AUTOSAR XML (schema 00050)
package /RB/PT/PCT_MDG1_FlatView/SwComponentTypes
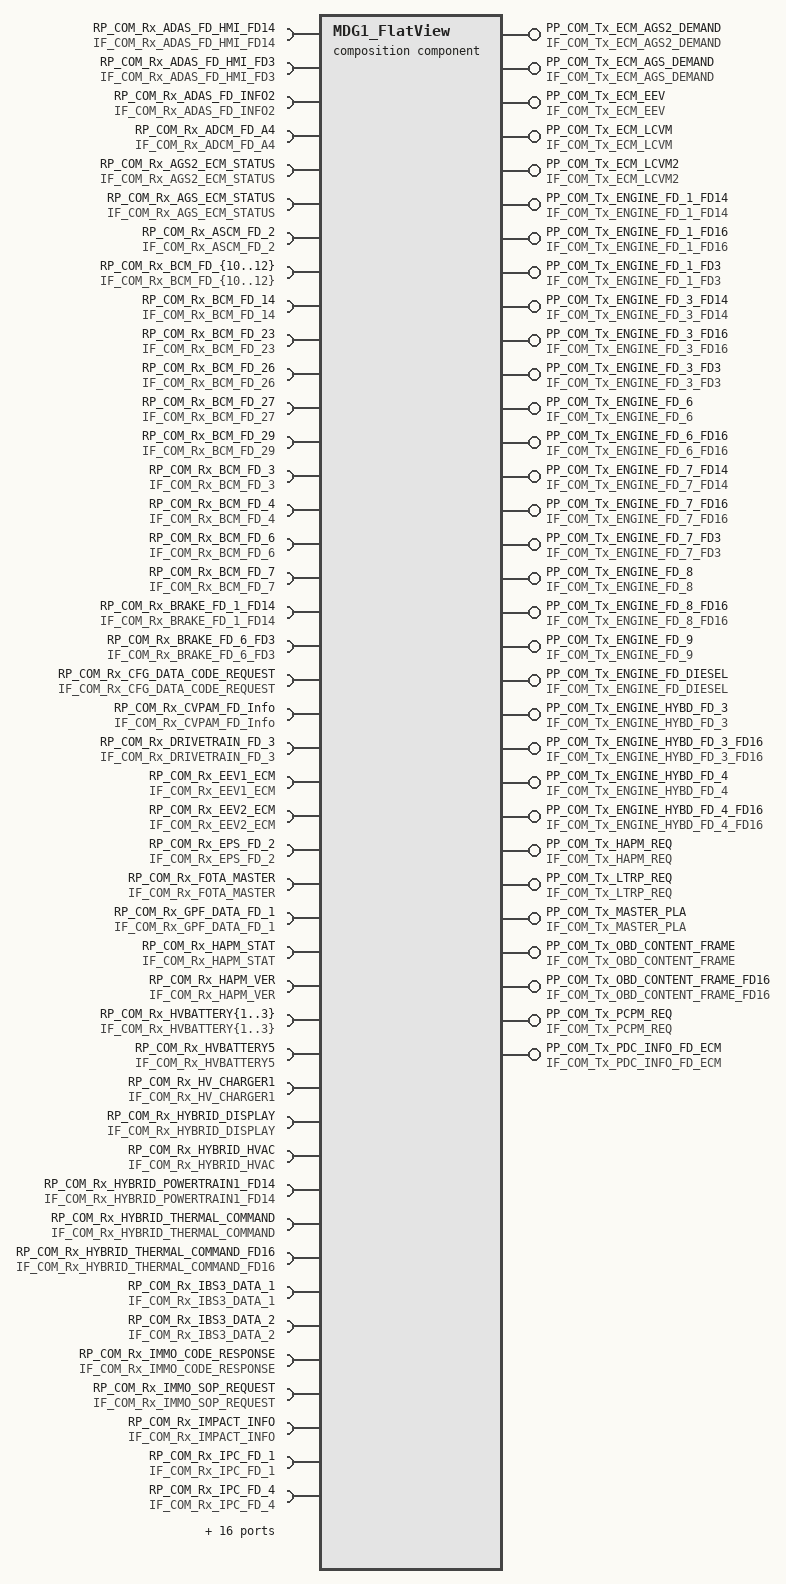
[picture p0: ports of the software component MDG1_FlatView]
  composition sw component type MDG1_FlatView
    31 x provide port:
      PP_COM_Tx_ECM_AGS2_DEMAND: provided-interface=IF_COM_Tx_ECM_AGS2_DEMAND
      PP_COM_Tx_ECM_AGS_DEMAND: provided-interface=IF_COM_Tx_ECM_AGS_DEMAND
      PP_COM_Tx_ECM_EEV: provided-interface=IF_COM_Tx_ECM_EEV
      PP_COM_Tx_ECM_LCVM: provided-interface=IF_COM_Tx_ECM_LCVM
      PP_COM_Tx_ECM_LCVM2: provided-interface=IF_COM_Tx_ECM_LCVM2
      PP_COM_Tx_ENGINE_FD_1_FD14: provided-interface=IF_COM_Tx_ENGINE_FD_1_FD14
      PP_COM_Tx_ENGINE_FD_1_FD16: provided-interface=IF_COM_Tx_ENGINE_FD_1_FD16
      PP_COM_Tx_ENGINE_FD_1_FD3: provided-interface=IF_COM_Tx_ENGINE_FD_1_FD3
      PP_COM_Tx_ENGINE_FD_3_FD14: provided-interface=IF_COM_Tx_ENGINE_FD_3_FD14
      PP_COM_Tx_ENGINE_FD_3_FD16: provided-interface=IF_COM_Tx_ENGINE_FD_3_FD16
      PP_COM_Tx_ENGINE_FD_3_FD3: provided-interface=IF_COM_Tx_ENGINE_FD_3_FD3
      PP_COM_Tx_ENGINE_FD_6: provided-interface=IF_COM_Tx_ENGINE_FD_6
      PP_COM_Tx_ENGINE_FD_6_FD16: provided-interface=IF_COM_Tx_ENGINE_FD_6_FD16
      PP_COM_Tx_ENGINE_FD_7_FD14: provided-interface=IF_COM_Tx_ENGINE_FD_7_FD14
      PP_COM_Tx_ENGINE_FD_7_FD16: provided-interface=IF_COM_Tx_ENGINE_FD_7_FD16
      PP_COM_Tx_ENGINE_FD_7_FD3: provided-interface=IF_COM_Tx_ENGINE_FD_7_FD3
      PP_COM_Tx_ENGINE_FD_8: provided-interface=IF_COM_Tx_ENGINE_FD_8
      PP_COM_Tx_ENGINE_FD_8_FD16: provided-interface=IF_COM_Tx_ENGINE_FD_8_FD16
      PP_COM_Tx_ENGINE_FD_9: provided-interface=IF_COM_Tx_ENGINE_FD_9
      PP_COM_Tx_ENGINE_FD_DIESEL: provided-interface=IF_COM_Tx_ENGINE_FD_DIESEL
      PP_COM_Tx_ENGINE_HYBD_FD_3: provided-interface=IF_COM_Tx_ENGINE_HYBD_FD_3
      PP_COM_Tx_ENGINE_HYBD_FD_3_FD16: provided-interface=IF_COM_Tx_ENGINE_HYBD_FD_3_FD16
      PP_COM_Tx_ENGINE_HYBD_FD_4: provided-interface=IF_COM_Tx_ENGINE_HYBD_FD_4
      PP_COM_Tx_ENGINE_HYBD_FD_4_FD16: provided-interface=IF_COM_Tx_ENGINE_HYBD_FD_4_FD16
      PP_COM_Tx_HAPM_REQ: provided-interface=IF_COM_Tx_HAPM_REQ
      PP_COM_Tx_LTRP_REQ: provided-interface=IF_COM_Tx_LTRP_REQ
      PP_COM_Tx_MASTER_PLA: provided-interface=IF_COM_Tx_MASTER_PLA
      PP_COM_Tx_OBD_CONTENT_FRAME: provided-interface=IF_COM_Tx_OBD_CONTENT_FRAME
      PP_COM_Tx_OBD_CONTENT_FRAME_FD16: provided-interface=IF_COM_Tx_OBD_CONTENT_FRAME_FD16
      PP_COM_Tx_PCPM_REQ: provided-interface=IF_COM_Tx_PCPM_REQ
      PP_COM_Tx_PDC_INFO_FD_ECM: provided-interface=IF_COM_Tx_PDC_INFO_FD_ECM
    64 x require port:
      RP_COM_Rx_ADAS_FD_HMI_FD14: required-interface=IF_COM_Rx_ADAS_FD_HMI_FD14
      RP_COM_Rx_ADAS_FD_HMI_FD3: required-interface=IF_COM_Rx_ADAS_FD_HMI_FD3
      RP_COM_Rx_ADAS_FD_INFO2: required-interface=IF_COM_Rx_ADAS_FD_INFO2
      RP_COM_Rx_ADCM_FD_A4: required-interface=IF_COM_Rx_ADCM_FD_A4
      RP_COM_Rx_AGS2_ECM_STATUS: required-interface=IF_COM_Rx_AGS2_ECM_STATUS
      RP_COM_Rx_AGS_ECM_STATUS: required-interface=IF_COM_Rx_AGS_ECM_STATUS
      RP_COM_Rx_ASCM_FD_2: required-interface=IF_COM_Rx_ASCM_FD_2
      RP_COM_Rx_BCM_FD_{10..12}: required-interface=IF_COM_Rx_BCM_FD_{10..12}
      RP_COM_Rx_BCM_FD_14: required-interface=IF_COM_Rx_BCM_FD_14
      RP_COM_Rx_BCM_FD_23: required-interface=IF_COM_Rx_BCM_FD_23
      RP_COM_Rx_BCM_FD_26: required-interface=IF_COM_Rx_BCM_FD_26
      RP_COM_Rx_BCM_FD_27: required-interface=IF_COM_Rx_BCM_FD_27
      RP_COM_Rx_BCM_FD_29: required-interface=IF_COM_Rx_BCM_FD_29
      RP_COM_Rx_BCM_FD_3: required-interface=IF_COM_Rx_BCM_FD_3
      RP_COM_Rx_BCM_FD_4: required-interface=IF_COM_Rx_BCM_FD_4
      RP_COM_Rx_BCM_FD_6: required-interface=IF_COM_Rx_BCM_FD_6
      RP_COM_Rx_BCM_FD_7: required-interface=IF_COM_Rx_BCM_FD_7
      RP_COM_Rx_BRAKE_FD_1_FD14: required-interface=IF_COM_Rx_BRAKE_FD_1_FD14
      RP_COM_Rx_BRAKE_FD_6_FD3: required-interface=IF_COM_Rx_BRAKE_FD_6_FD3
      RP_COM_Rx_CFG_DATA_CODE_REQUEST: required-interface=IF_COM_Rx_CFG_DATA_CODE_REQUEST
      RP_COM_Rx_CVPAM_FD_Info: required-interface=IF_COM_Rx_CVPAM_FD_Info
      RP_COM_Rx_DRIVETRAIN_FD_3: required-interface=IF_COM_Rx_DRIVETRAIN_FD_3
      RP_COM_Rx_EEV1_ECM: required-interface=IF_COM_Rx_EEV1_ECM
      RP_COM_Rx_EEV2_ECM: required-interface=IF_COM_Rx_EEV2_ECM
      RP_COM_Rx_EPS_FD_2: required-interface=IF_COM_Rx_EPS_FD_2
      RP_COM_Rx_FOTA_MASTER: required-interface=IF_COM_Rx_FOTA_MASTER
      RP_COM_Rx_GPF_DATA_FD_1: required-interface=IF_COM_Rx_GPF_DATA_FD_1
      RP_COM_Rx_HAPM_STAT: required-interface=IF_COM_Rx_HAPM_STAT
      RP_COM_Rx_HAPM_VER: required-interface=IF_COM_Rx_HAPM_VER
      RP_COM_Rx_HVBATTERY{1..3}: required-interface=IF_COM_Rx_HVBATTERY{1..3}
      RP_COM_Rx_HVBATTERY5: required-interface=IF_COM_Rx_HVBATTERY5
      RP_COM_Rx_HV_CHARGER1: required-interface=IF_COM_Rx_HV_CHARGER1
      RP_COM_Rx_HYBRID_DISPLAY: required-interface=IF_COM_Rx_HYBRID_DISPLAY
      RP_COM_Rx_HYBRID_HVAC: required-interface=IF_COM_Rx_HYBRID_HVAC
      RP_COM_Rx_HYBRID_POWERTRAIN1_FD14: required-interface=IF_COM_Rx_HYBRID_POWERTRAIN1_FD14
      RP_COM_Rx_HYBRID_THERMAL_COMMAND: required-interface=IF_COM_Rx_HYBRID_THERMAL_COMMAND
      RP_COM_Rx_HYBRID_THERMAL_COMMAND_FD16: required-interface=IF_COM_Rx_HYBRID_THERMAL_COMMAND_FD16
      RP_COM_Rx_IBS3_DATA_1: required-interface=IF_COM_Rx_IBS3_DATA_1
      RP_COM_Rx_IBS3_DATA_2: required-interface=IF_COM_Rx_IBS3_DATA_2
      RP_COM_Rx_IMMO_CODE_RESPONSE: required-interface=IF_COM_Rx_IMMO_CODE_RESPONSE
      RP_COM_Rx_IMMO_SOP_REQUEST: required-interface=IF_COM_Rx_IMMO_SOP_REQUEST
      RP_COM_Rx_IMPACT_INFO: required-interface=IF_COM_Rx_IMPACT_INFO
      RP_COM_Rx_IPC_FD_1: required-interface=IF_COM_Rx_IPC_FD_1
      RP_COM_Rx_IPC_FD_4: required-interface=IF_COM_Rx_IPC_FD_4
      RP_COM_Rx_IPC_VEHICLE_SETUP: required-interface=IF_COM_Rx_IPC_VEHICLE_SETUP
      RP_COM_Rx_LCVM2_ECM: required-interface=IF_COM_Rx_LCVM2_ECM
      RP_COM_Rx_LCVM_ECM: required-interface=IF_COM_Rx_LCVM_ECM
      RP_COM_Rx_LTRP_STAT: required-interface=IF_COM_Rx_LTRP_STAT
      RP_COM_Rx_LTRP_VER: required-interface=IF_COM_Rx_LTRP_VER
      RP_COM_Rx_PCPM_Stat: required-interface=IF_COM_Rx_PCPM_Stat
      RP_COM_Rx_PCPM_VER: required-interface=IF_COM_Rx_PCPM_VER
      RP_COM_Rx_PLA_INFO: required-interface=IF_COM_Rx_PLA_INFO
      RP_COM_Rx_PT_SYSTEM_FD_1_FD3: required-interface=IF_COM_Rx_PT_SYSTEM_FD_1_FD3
      RP_COM_Rx_RFHUB_FD_1: required-interface=IF_COM_Rx_RFHUB_FD_1
      RP_COM_Rx_STEERING1: required-interface=IF_COM_Rx_STEERING1
      RP_COM_Rx_TELEMATIC_FD_1: required-interface=IF_COM_Rx_TELEMATIC_FD_1
      RP_COM_Rx_TELEMATIC_FD_11: required-interface=IF_COM_Rx_TELEMATIC_FD_11
      RP_COM_Rx_TELEMATIC_FD_14: required-interface=IF_COM_Rx_TELEMATIC_FD_14
      RP_COM_Rx_TELEMATIC_FD_5: required-interface=IF_COM_Rx_TELEMATIC_FD_5
      RP_COM_Rx_VSIM_FD_1: required-interface=IF_COM_Rx_VSIM_FD_1
    191 x component:
      AC_CluRlyDigOutp: type=IoSigDioOutp_SwSStellantis
      AirCdngPSnsrAdcInpSwc: type=IoSigAdc_SwSStellantis
      AllGrPosnSnsr1PwmInp: type=IoSigPwmInp_SwSStellantis
      AllGrPosnSnsr2PwmInp: type=IoSigPwmInp_SwSStellantis
      AlterFieCtrlPwmOutp: type=IoSigPwmOutp_SwSStellantis
      BoostTemp1AdcInpSwc: type=IoSigAdc_SwSStellantis
      BoostTemp2AdcInpSwc: type=IoSigAdc_SwSStellantis
      BrkPdlPosnSnsrAdcInp: type=IoSigAdc_SwSStellantis
      BrkSwDigInp: type=IoSigDioInp_SwSStellantis
      CEGR_PosnSns: type=SentStack_SwSStellantis
      CPT_BswM: type=BswM
      CPT_ComCIL_Adapt: type=SWC_ComCIL_Adapt
      CPT_ComDia_Dcm_Rte_Adapter: type=ComDia_Dcm_Rte_Adapter
      CPT_ComM: type=ComM
      CPT_ComScl_EngLin: type=SWC_ComScl_EngLin
      CPT_ComScl_EngLin_Scl: type=SWC_ComScl_EngLin_Scl
      CPT_ComScl_NetMtrx: type=SWC_ComScl_NetMtrx
      CPT_ComScl_NetMtrx2: type=SWC_ComScl_NetMtrx2
      CPT_ComScl_NetMtrx2_Scl: type=SWC_ComScl_NetMtrx2_Scl
      CPT_ComScl_NetMtrx3: type=SWC_ComScl_NetMtrx3
      CPT_ComScl_NetMtrx3_Scl: type=SWC_ComScl_NetMtrx3_Scl
      CPT_ComScl_NetMtrx_Scl: type=SWC_ComScl_NetMtrx_Scl
      CPT_Csm: type=Csm
      CPT_Dcm: type=Dcm
      CPT_Dem: type=Dem
      CPT_Det: type=Det
      CPT_ESC_EveCfg: type=ESC_EveCfg
      CPT_ESC_HwIntrptEveGen: type=ESC_HwIntrptEveGen
      CPT_ESC_Ladp: type=ESC_Ladp
      CPT_ESC_OsTskActvnHndlr: type=ESC_OsTskActvnHndlr
      CPT_EcuM: type=EcuM
      CPT_Epm_Ladp: type=Epm_Ladp
      CPT_FiM: type=FiM
      CPT_IoSigAdc_SwSStellantisParm: type=IoSigAdc_SwSStellantisParm
      CPT_IoSigDioInp_SwSStellantisParam: type=IoSigDioInp_SwSStellantisParam
      CPT_IoSigDioOutp_SwSStellantisParam: type=IoSigDioOutp_SwSStellantisParam
      CPT_IoSigPwmInp_SwSStellantisParm: type=IoSigPwmInp_SwSStellantisParm
      CPT_IoSigPwmOutp_SwSStellantisParm: type=IoSigPwmOutp_SwSStellantisParm
      CPT_KeyM: type=KeyM
      CPT_NvM: type=NvM
      CPT_SWC_VcodProxi: type=SWC_VcodProxi
      CPT_SecOC: type=SecOC
      CPT_SentStack_SwSStellantisParm: type=SentStack_SwSStellantisParm
      CPT_SysC_Ladp: type=SysC_Ladp
      CPT_WdgM: type=WdgM
      CPT_esc_stack: type=esc_stack
      CPT_esc_tasklink: type=esc_tasklink
      CPT_rba_DiagLib: type=rba_DiagLib
      CPT_rba_IoDiagHbr: type=rba_IoDiagHbr
      CPT_rba_IoDiagHlfBr: type=rba_IoDiagHlfBr
      CPT_rba_IoDiagPs: type=rba_IoDiagPs
      CPT_rba_IoDiagPwr: type=rba_IoDiagPwr
      CPT_rba_IoSigAdc: type=rba_IoSigAdc
      CPT_rba_IoSigDio: type=rba_IoSigDio
      CPT_rba_IoSigHlfBr: type=rba_IoSigHlfBr
      CPT_rba_IoSigIcu: type=rba_IoSigIcu
      CPT_rba_IoSigObs: type=rba_IoSigObs
      CPT_rba_IoSigPwm: type=rba_IoSigPwm
      CPT_rba_IoSigPwr: type=rba_IoSigPwr
      CPT_rba_IoSigRtc: type=rba_IoSigRtc
      CPT_rba_OsArSchedExtn_OS: type=rba_OsArSchedExtn_OS
      CPT_rba_OsShell: type=rba_OsShell
      CPT_rba_SyC_States: type=rba_SyC_States
      CPT_rba_SyC_States_Cfg_0_Q_1: type=rba_SyC_States_Cfg_0_Q_1
      CPT_rba_SyC_States_Cfg_1_B_1: type=rba_SyC_States_Cfg_1_B_1
      CPT_rba_SyC_States_Cfg_{1..3}_Q_1: type=rba_SyC_States_Cfg_{1..3}_Q_1
      CPT_rbf_SftyHw_ErrMngtModl: type=rbf_SftyHw_ErrMngtModl
      CPT_rbf_SftyHw_ProgFlowChk: type=rbf_SftyHw_ProgFlowChk
      CPT_rbf_SftyHw_ShtOffPahPwrStg: type=rbf_SftyHw_ShtOffPahPwrStg
      CPT_rbm_DSM_Conf: type=rbm_DSM_Conf
      CPT_rbm_MilHndlr: type=rbm_MilHndlr
      CalInp1AdcInpSwc: type=IoSigAdc_SwSStellantis
      CalInp2AdcInpSwc: type=IoSigAdc_SwSStellantis
      CluInterLockSwDigInp: type=IoSigDioInp_SwSStellantis
      CluSnsAdcInp: type=IoSigAdc_SwSStellantis
      CmprInletTempAdcInp: type=IoSigAdc_SwSStellantis
      CoEng_SwSStellantis: type=CoEng_SwSStellantis
      ColdCrkCasePSnsrAdcInpSwc: type=IoSigAdc_SwSStellantis
      CoolEgrTAdcInpSwc: type=IoSigAdc_SwSStellantis
      Coolt3WayVlvAdcInpSwc: type=IoSigAdc_SwSStellantis
      CooltInletTempAdcInpSwc: type=IoSigAdc_SwSStellantis
      CrkBattMonrAdcInpSwc: type=IoSigAdc_SwSStellantis
      DMTLLkPmpDigOutp: type=IoSigDioOutp_SwSStellantis
      DP_VlvPosnSns: type=SentStack_SwSStellantis
      DSM_SwSStellantis: type=DSM_SwSStellantis
      DualFuTankEnblRlyDigOutp: type=IoSigDioOutp_SwSStellantis
      DynoFuDsblReqSwDigInp: type=IoSigDioInp_SwSStellantis
      ECM_WakeUpDigInp: type=IoSigDioInp_SwSStellantis
      EGRCoolr_DeltAbsPresSnsr: type=SentStack_SwSStellantis
      ELCM_ChgOvrVlvDigOutp: type=IoSigDioOutp_SwSStellantis
      ELCM_VacPmpPwmOutp: type=IoSigPwmOutp_SwSStellantis
      ElecPhsrDiagPwmInp: type=IoSigPwmInp_SwSStellantis
      ElecPhsrMtrCmdOutpPwmOutp: type=IoSigPwmOutp_SwSStellantis
      ElectcVacPmpRlyDigOutp: type=IoSigDioOutp_SwSStellantis
      EngCooltTAdcInpSwc: type=IoSigAdc_SwSStellantis
      EngSwtBattAdcInpSwc: type=IoSigAdc_SwSStellantis
      EnvP_SwSStellantis: type=EnvP_SwSStellantis
      Epm_SwSStellantis: type=Epm_SwSStellantis
      Epm_SwSStellantis_PSwc: type=Epm_SwSStellantis_PSwc
      EvapLkChkMonSnsAdcInpSwc: type=IoSigAdc_SwSStellantis
      FPCMFb1PwmInp: type=IoSigPwmInp_SwSStellantis
      FiveVoltAuxAdcInpSwc: type=IoSigAdc_SwSStellantis
      FiveVoltOutpAdcInpSwc: type=IoSigAdc_SwSStellantis
      FiveVoltSnsAdcInpSwc: type=IoSigAdc_SwSStellantis
      FuDoorDigOutp: type=IoSigDioOutp_SwSStellantis
      FuDoorSwDigInp: type=IoSigDioInp_SwSStellantis
      FuPmpCtlMdul2CmdPwmOutp: type=IoSigPwmOutp_SwSStellantis
      FuPmpCtlMdulCmdPwmOutp: type=IoSigPwmOutp_SwSStellantis
      FuTankIsolnVlvDigOutp: type=IoSigDioOutp_SwSStellantis
      FuTankPSnsrAdcInpSwc: type=IoSigAdc_SwSStellantis
      GEVlv_SwSStellantis: type=GEVlv_SwSStellantis
      GPF_DeltAbsPresSnsr1: type=SentStack_SwSStellantis
      GPF_DeltAbsPresSnsr2: type=SentStack_SwSStellantis
      GdiFuRailP1AdcInpSwc: type=IoSigAdc_SwSStellantis
      GdiFuRailP2AdcInpSwc: type=IoSigAdc_SwSStellantis
      HTR_MeclWtrPmpActrPwmOutp: type=IoSigPwmOutp_SwSStellantis
      HTR_TempCtrlVlvSolnPwmOutp: type=IoSigPwmOutp_SwSStellantis
      Hbrdg_Coold_EGR: type=IoSigHbrdg_SwSStellantis
      Hbrdg_DP: type=IoSigHbrdg_SwSStellantis
      Hbrdg_ETC_Motor: type=IoSigHbrdg_SwSStellantis
      Hbrdg_VarGeomTrb: type=IoSigHbrdg_SwSStellantis
      Hbrdg_Wg1: type=IoSigHbrdg_SwSStellantis
      HiTRadrOutlTSnsrAdcInpSwc: type=IoSigAdc_SwSStellantis
      HoodAjarAdcInpSwc: type=IoSigAdc_SwSStellantis
      IgnCl_SwSStellantis: type=IgnCl_SwSStellantis
      IgnRunStrtSwDigInp: type=IoSigDioInp_SwSStellantis
      InjSyG_SwSStellantis: type=InjSyG_SwSStellantis
      InjVvGPfi_SwSStellantis: type=InjVvGPfi_SwSStellantis
      InjVvG_SwSStellantis: type=InjVvG_SwSStellantis
      InrushCircRlyDigOutp: type=IoSigDioOutp_SwSStellantis
      IntkAirTAdcInpSwc: type=IoSigAdc_SwSStellantis
      IoSigAdc_SwSStellantisParm: type=IoSigAdc_SwSStellantisParm
      IoSigDioInp_SwSStellantisParam: type=IoSigDioInp_SwSStellantisParam
      IoSigDioOutp_SwSStellantisParam: type=IoSigDioOutp_SwSStellantisParam
      IoSigHbrdg_SwSStellantisParam: type=IoSigHbrdg_SwSStellantisParam
      IoSigIfAdapt_SwSStellantis: type=IoSigIfAdapt_SwSStellantis
      IoSigPwmInp_SwSStellantisParm: type=IoSigPwmInp_SwSStellantisParm
      IoSigPwmOutp_SwSStellantisParm: type=IoSigPwmOutp_SwSStellantisParm
      IoSigPwr_SwSStellantis: type=IoSigPwr_SwSStellantis
      KnDet_SwSStellantis: type=KnDet_SwSStellantis
      LoPFuSnsrAdcInpSwc: type=IoSigAdc_SwSStellantis
      LoPresFuPmpRlyDigOutp: type=IoSigDioOutp_SwSStellantis
      MAF_Hum_Snsr: type=SentStack_SwSStellantis
      MFVlv_SwSStellantis: type=MFVlv_SwSStellantis
      MaiRlyDigOutp: type=IoSigDioOutp_SwSStellantis
      MakeUpAirVlvDigOutp: type=IoSigDioOutp_SwSStellantis
      MnfldAirPAdcInpSwc: type=IoSigAdc_SwSStellantis
      MnfldGasTAdcInpSwc: type=IoSigAdc_SwSStellantis
      NVLD_SwDigInp: type=IoSigDioInp_SwSStellantis
      O2Snsr_SwSStellantis: type=O2Snsr_SwSStellantis
      OBD_PurgVentVlvDigOutp: type=IoSigDioOutp_SwSStellantis
      OilLvlSnsrPwmInp: type=IoSigPwmInp_SwSStellantis
      OilPSnsrAdcInpSwc: type=IoSigAdc_SwSStellantis
      OilShutOffValveFbAdcInp: type=IoSigAdc_SwSStellantis
      OilShutOffVlvDigOutp: type=IoSigDioOutp_SwSStellantis
      OilTSnsrAdcInpSwc: type=IoSigAdc_SwSStellantis
      PFIFuRailPressAdcInp: type=IoSigAdc_SwSStellantis
      PFIFuRailTempAdcInp: type=IoSigAdc_SwSStellantis
      PedlValSnsr1AdcInpSwc: type=IoSigAdc_SwSStellantis
      PedlValSnsr2AdcInpSwc: type=IoSigAdc_SwSStellantis
      PedlValSnsr2AuxAdcInpSwc: type=IoSigAdc_SwSStellantis
      PurgSoln2PwmOutp: type=IoSigPwmOutp_SwSStellantis
      PurgSolnPwmOutp: type=IoSigPwmOutp_SwSStellantis
      RadrFanCtrlPwmPwmOutp: type=IoSigPwmOutp_SwSStellantis
      RadrFanRlyHiSpdDigOutp: type=IoSigDioOutp_SwSStellantis
      ReAxleTempSnsrAdcInp: type=IoSigAdc_SwSStellantis
      SecdAirPmpRlyDigOutp: type=IoSigDioOutp_SwSStellantis
      SecdAirShutOffSoln1DigOutp: type=IoSigDioOutp_SwSStellantis
      SentStack_SwSStellantisParm: type=SentStack_SwSStellantisParm
      SrgSoln1DigOutp: type=IoSigDioOutp_SwSStellantis
      SrgSoln2DigOutp: type=IoSigDioOutp_SwSStellantis
      StrtrRlyDigOutp: type=IoSigDioOutp_SwSStellantis
      StrtrRlyFbDigInp: type=IoSigDioInp_SwSStellantis
      SwilEngMnt1DigOutp: type=IoSigDioOutp_SwSStellantis
      SwilEngMnt2DigOutp: type=IoSigDioOutp_SwSStellantis
      SysU12VoltAdcInpSwc: type=IoSigAdc_SwSStellantis
      TOH_ShutOffVlvDigOutp: type=IoSigDioOutp_SwSStellantis
      ThrIntkGasTAdcInpSwc: type=IoSigAdc_SwSStellantis
      ThrIntkPAdcInpSwc: type=IoSigAdc_SwSStellantis
      ThrPosnSnsr1AdcInpSwc: type=IoSigAdc_SwSStellantis
      ThrPosnSnsr2AdcInpSwc: type=IoSigAdc_SwSStellantis
      VapBlockingVlvDigOutp: type=IoSigDioOutp_SwSStellantis
      VarGeomTrbFb: type=IoSigAdc_SwSStellantis
      VarOilSolnPwmOutp: type=IoSigPwmOutp_SwSStellantis
      VvtExh1PwmOutp: type=IoSigPwmOutp_SwSStellantis
      VvtIntk1PwmOutp: type=IoSigPwmOutp_SwSStellantis
      WgPosn1AdcInpSwc: type=IoSigAdc_SwSStellantis
      WgPosn2AdcInpSwc: type=IoSigAdc_SwSStellantis
      WgSolnPwmOutp: type=IoSigPwmOutp_SwSStellantis
    connect CPT_ComDia_Dcm_Rte_Adapter.DataServices_D9E08_VeRPMR_n_EngSpdResl1 -> CPT_Dcm.DataServices_D9E08_VeRPMR_n_EngSpdResl1
    connect CPT_ComDia_Dcm_Rte_Adapter.DataServices_D9E08_VeVSPR_v_VehSpd -> CPT_Dcm.DataServices_D9E08_VeVSPR_v_VehSpd
    connect CPT_ComDia_Dcm_Rte_Adapter.DataServices_DE102_VeCAMD_Cnt_P0340_RunMatrMax -> CPT_Dcm.DataServices_DE102_VeCAMD_Cnt_P0340_RunMatrMax
    connect CPT_ComDia_Dcm_Rte_Adapter.DataServices_DE102_VeCAMD_Cnt_P0340_StrtMatrMax -> CPT_Dcm.DataServices_DE102_VeCAMD_Cnt_P0340_StrtMatrMax
    connect CPT_ComDia_Dcm_Rte_Adapter.DataServices_DE102_VeCAMD_Cnt_P0345_StrtMatrMax -> CPT_Dcm.DataServices_DE102_VeCAMD_Cnt_P0345_StrtMatrMax
    connect CPT_ComDia_Dcm_Rte_Adapter.DataServices_DE102_VeCAMR_Cnt_Exh1MatrCntMaxReachd -> CPT_Dcm.DataServices_DE102_VeCAMR_Cnt_Exh1MatrCntMaxReachd
    connect CPT_ComDia_Dcm_Rte_Adapter.DataServices_DE102_VeCAMR_Cnt_Exh2MatrCntMaxReachd -> CPT_Dcm.DataServices_DE102_VeCAMR_Cnt_Exh2MatrCntMaxReachd
    connect CPT_ComDia_Dcm_Rte_Adapter.DataServices_DE102_VeCAMR_Cnt_Intk1MatrCntMaxReachd -> CPT_Dcm.DataServices_DE102_VeCAMR_Cnt_Intk1MatrCntMaxReachd
    connect CPT_ComDia_Dcm_Rte_Adapter.DataServices_DE102_VeCAMR_Cnt_Intk2MatrCntMaxReachd -> CPT_Dcm.DataServices_DE102_VeCAMR_Cnt_Intk2MatrCntMaxReachd
    connect CPT_ComDia_Dcm_Rte_Adapter.DataServices_DE102_VeCAMR_phi_Exh1MaxDifReachd -> CPT_Dcm.DataServices_DE102_VeCAMR_phi_Exh1MaxDifReachd
    connect CPT_ComDia_Dcm_Rte_Adapter.DataServices_DE102_VeCAMR_phi_Exh2MaxDifReachd -> CPT_Dcm.DataServices_DE102_VeCAMR_phi_Exh2MaxDifReachd
    connect CPT_ComDia_Dcm_Rte_Adapter.DataServices_DE102_VeCAMR_phi_Intk1MaxDifReachd -> CPT_Dcm.DataServices_DE102_VeCAMR_phi_Intk1MaxDifReachd
    connect CPT_ComDia_Dcm_Rte_Adapter.DataServices_DE102_VeCAMR_phi_Intk2MaxDifReachd -> CPT_Dcm.DataServices_DE102_VeCAMR_phi_Intk2MaxDifReachd
    connect CPT_ComDia_Dcm_Rte_Adapter.DataServices_DE102_VeCRKO_Cnt_MaxCrksftStrtUpNotSeenTmr -> CPT_Dcm.DataServices_DE102_VeCRKO_Cnt_MaxCrksftStrtUpNotSeenTmr
    connect CPT_ComDia_Dcm_Rte_Adapter.DataServices_DE102_VeCRKO_Cnt_MaxCrksftUnlckMatrCntr -> CPT_Dcm.DataServices_DE102_VeCRKO_Cnt_MaxCrksftUnlckMatrCntr
    connect CPT_ComDia_Dcm_Rte_Adapter.DataServices_DE102_VeCRKO_Cnt_MaxMissInRunMatrCnt -> CPT_Dcm.DataServices_DE102_VeCRKO_Cnt_MaxMissInRunMatrCnt
    connect CPT_ComDia_Dcm_Rte_Adapter.DataServices_DE111_VeOHTR_R_OxSnsrHtrDsBnk1Raw -> CPT_Dcm.DataServices_DE111_VeOHTR_R_OxSnsrHtrDsBnk1Raw
    connect CPT_ComDia_Dcm_Rte_Adapter.DataServices_DE111_VeOHTR_R_OxSnsrHtrDsBnk2Raw -> CPT_Dcm.DataServices_DE111_VeOHTR_R_OxSnsrHtrDsBnk2Raw
    connect CPT_ComDia_Dcm_Rte_Adapter.DataServices_DE111_VeOHTR_R_OxSnsrHtrUsBnk1Raw -> CPT_Dcm.DataServices_DE111_VeOHTR_R_OxSnsrHtrUsBnk1Raw
    connect CPT_ComDia_Dcm_Rte_Adapter.DataServices_DE111_VeOHTR_R_OxSnsrHtrUsBnk2Raw -> CPT_Dcm.DataServices_DE111_VeOHTR_R_OxSnsrHtrUsBnk2Raw
    connect CPT_ComDia_Dcm_Rte_Adapter.DataServices_DE113_VeCRKO_b_ETPU_SyncnSts -> CPT_Dcm.DataServices_DE113_VeCRKO_b_ETPU_SyncnSts
    connect CPT_ComDia_Dcm_Rte_Adapter.DataServices_DE113_VeLLFO_g_ETPU_InjrPinStsMimic -> CPT_Dcm.DataServices_DE113_VeLLFO_g_ETPU_InjrPinStsMimic
    connect CPT_ComDia_Dcm_Rte_Adapter.DataServices_DE113_VeLLSO_y_IgnPinStsMimic -> CPT_Dcm.DataServices_DE113_VeLLSO_y_IgnPinStsMimic
    connect CPT_ComDia_Dcm_Rte_Adapter.DataServices_DE124_CamsftPosnSnsrExh1CircIntmFlt_EnaStsReg -> CPT_Dcm.DataServices_DE124_CamsftPosnSnsrExh1CircIntmFlt_EnaStsReg
    connect CPT_ComDia_Dcm_Rte_Adapter.DataServices_DE124_CrksftPosnCamsftPosnCorrExh1Flt_EnaStsReg -> CPT_Dcm.DataServices_DE124_CrksftPosnCamsftPosnCorrExh1Flt_EnaStsReg
    connect CPT_ComDia_Dcm_Rte_Adapter.DataServices_DE124_CrksftPosnSnsr1CircFlt_EnaStsReg -> CPT_Dcm.DataServices_DE124_CrksftPosnSnsr1CircFlt_EnaStsReg
    connect CPT_ComDia_Dcm_Rte_Adapter.DataServices_DE124_VeCRKD_y_P0339_EnblSts -> CPT_Dcm.DataServices_DE124_VeCRKD_y_P0339_EnblSts
    connect CPT_ComDia_Dcm_Rte_Adapter.DataServices_DE124_VeDEMD_y_C053D_EventStatus -> CPT_Dcm.DataServices_DE124_VeDEMD_y_C053D_EventStatus
    connect CPT_ComDia_Dcm_Rte_Adapter.DataServices_DE124_VeDEMD_y_C10F5_EventStatus -> CPT_Dcm.DataServices_DE124_VeDEMD_y_C10F5_EventStatus
    connect CPT_ComDia_Dcm_Rte_Adapter.DataServices_DE124_VeDEMD_y_P000A_EventStatus -> CPT_Dcm.DataServices_DE124_VeDEMD_y_P000A_EventStatus
    connect CPT_ComDia_Dcm_Rte_Adapter.DataServices_DE124_VeDEMD_y_P000B_EventStatus -> CPT_Dcm.DataServices_DE124_VeDEMD_y_P000B_EventStatus
    connect CPT_ComDia_Dcm_Rte_Adapter.DataServices_DE124_VeDEMD_y_P000C_EventStatus -> CPT_Dcm.DataServices_DE124_VeDEMD_y_P000C_EventStatus
    connect CPT_ComDia_Dcm_Rte_Adapter.DataServices_DE124_VeDEMD_y_P000D_EventStatus -> CPT_Dcm.DataServices_DE124_VeDEMD_y_P000D_EventStatus
    connect CPT_ComDia_Dcm_Rte_Adapter.DataServices_DE124_VeDEMD_y_P0016_EventStatus -> CPT_Dcm.DataServices_DE124_VeDEMD_y_P0016_EventStatus
    connect CPT_ComDia_Dcm_Rte_Adapter.DataServices_DE124_VeDEMD_y_P0071_EventStatus -> CPT_Dcm.DataServices_DE124_VeDEMD_y_P0071_EventStatus
    connect CPT_ComDia_Dcm_Rte_Adapter.DataServices_DE124_VeDEMD_y_P0116_EventStatus -> CPT_Dcm.DataServices_DE124_VeDEMD_y_P0116_EventStatus
    connect CPT_ComDia_Dcm_Rte_Adapter.DataServices_DE124_VeDEMD_y_P0125_EventStatus -> CPT_Dcm.DataServices_DE124_VeDEMD_y_P0125_EventStatus
    connect CPT_ComDia_Dcm_Rte_Adapter.DataServices_DE124_VeDEMD_y_P0128_EventStatus -> CPT_Dcm.DataServices_DE124_VeDEMD_y_P0128_EventStatus
    connect CPT_ComDia_Dcm_Rte_Adapter.DataServices_DE124_VeDEMD_y_P{0131..0133}_EventStatus -> CPT_Dcm.DataServices_DE124_VeDEMD_y_P{0131..0133}_EventStatus
    connect CPT_ComDia_Dcm_Rte_Adapter.DataServices_DE124_VeDEMD_y_P0135_EventStatus -> CPT_Dcm.DataServices_DE124_VeDEMD_y_P0135_EventStatus
    connect CPT_ComDia_Dcm_Rte_Adapter.DataServices_DE124_VeDEMD_y_P{0137..0141}_EventStatus -> CPT_Dcm.DataServices_DE124_VeDEMD_y_P{0137..0141}_EventStatus
    connect CPT_ComDia_Dcm_Rte_Adapter.DataServices_DE124_VeDEMD_y_P{0151..0153}_EventStatus -> CPT_Dcm.DataServices_DE124_VeDEMD_y_P{0151..0153}_EventStatus
    connect CPT_ComDia_Dcm_Rte_Adapter.DataServices_DE124_VeDEMD_y_P0155_EventStatus -> CPT_Dcm.DataServices_DE124_VeDEMD_y_P0155_EventStatus
    connect CPT_ComDia_Dcm_Rte_Adapter.DataServices_DE124_VeDEMD_y_P{0157..0161}_EventStatus -> CPT_Dcm.DataServices_DE124_VeDEMD_y_P{0157..0161}_EventStatus
    connect CPT_ComDia_Dcm_Rte_Adapter.DataServices_DE124_VeDEMD_y_P0171_EventStatus -> CPT_Dcm.DataServices_DE124_VeDEMD_y_P0171_EventStatus
    connect CPT_ComDia_Dcm_Rte_Adapter.DataServices_DE124_VeDEMD_y_P0172_EventStatus -> CPT_Dcm.DataServices_DE124_VeDEMD_y_P0172_EventStatus
    connect CPT_ComDia_Dcm_Rte_Adapter.DataServices_DE124_VeDEMD_y_P0174_EventStatus -> CPT_Dcm.DataServices_DE124_VeDEMD_y_P0174_EventStatus
    connect CPT_ComDia_Dcm_Rte_Adapter.DataServices_DE124_VeDEMD_y_P0175_EventStatus -> CPT_Dcm.DataServices_DE124_VeDEMD_y_P0175_EventStatus
    connect CPT_ComDia_Dcm_Rte_Adapter.DataServices_DE124_VeDEMD_y_P018B_EventStatus -> CPT_Dcm.DataServices_DE124_VeDEMD_y_P018B_EventStatus
    connect CPT_ComDia_Dcm_Rte_Adapter.DataServices_DE124_VeDEMD_y_P0196_EventStatus -> CPT_Dcm.DataServices_DE124_VeDEMD_y_P0196_EventStatus
    connect CPT_ComDia_Dcm_Rte_Adapter.DataServices_DE124_VeDEMD_y_P0298_EventStatus -> CPT_Dcm.DataServices_DE124_VeDEMD_y_P0298_EventStatus
    connect CPT_ComDia_Dcm_Rte_Adapter.DataServices_DE124_VeDEMD_y_P{0300..0308}_EventStatus -> CPT_Dcm.DataServices_DE124_VeDEMD_y_P{0300..0308}_EventStatus
    connect CPT_ComDia_Dcm_Rte_Adapter.DataServices_DE124_VeDEMD_y_P0325_EventStatus -> CPT_Dcm.DataServices_DE124_VeDEMD_y_P0325_EventStatus
    connect CPT_ComDia_Dcm_Rte_Adapter.DataServices_DE124_VeDEMD_y_P0330_EventStatus -> CPT_Dcm.DataServices_DE124_VeDEMD_y_P0330_EventStatus
    connect CPT_ComDia_Dcm_Rte_Adapter.DataServices_DE124_VeDEMD_y_P0335_EventStatus -> CPT_Dcm.DataServices_DE124_VeDEMD_y_P0335_EventStatus
    connect CPT_ComDia_Dcm_Rte_Adapter.DataServices_DE124_VeDEMD_y_P0339_EventStatus -> CPT_Dcm.DataServices_DE124_VeDEMD_y_P0339_EventStatus
    connect CPT_ComDia_Dcm_Rte_Adapter.DataServices_DE124_VeDEMD_y_P0340_EventStatus -> CPT_Dcm.DataServices_DE124_VeDEMD_y_P0340_EventStatus
    connect CPT_ComDia_Dcm_Rte_Adapter.DataServices_DE124_VeDEMD_y_P0344_EventStatus -> CPT_Dcm.DataServices_DE124_VeDEMD_y_P0344_EventStatus
    connect CPT_ComDia_Dcm_Rte_Adapter.DataServices_DE124_VeDEMD_y_P0420_EventStatus -> CPT_Dcm.DataServices_DE124_VeDEMD_y_P0420_EventStatus
    connect CPT_ComDia_Dcm_Rte_Adapter.DataServices_DE124_VeDEMD_y_P0430_EventStatus -> CPT_Dcm.DataServices_DE124_VeDEMD_y_P0430_EventStatus
    connect CPT_ComDia_Dcm_Rte_Adapter.DataServices_DE124_VeDEMD_y_P0461_EventStatus -> CPT_Dcm.DataServices_DE124_VeDEMD_y_P0461_EventStatus
    connect CPT_ComDia_Dcm_Rte_Adapter.DataServices_DE124_VeDEMD_y_P0501_EventStatus -> CPT_Dcm.DataServices_DE124_VeDEMD_y_P0501_EventStatus
    connect CPT_ComDia_Dcm_Rte_Adapter.DataServices_DE124_VeDEMD_y_P0506_EventStatus -> CPT_Dcm.DataServices_DE124_VeDEMD_y_P0506_EventStatus
    connect CPT_ComDia_Dcm_Rte_Adapter.DataServices_DE124_VeDEMD_y_P0507_EventStatus -> CPT_Dcm.DataServices_DE124_VeDEMD_y_P0507_EventStatus
    connect CPT_ComDia_Dcm_Rte_Adapter.DataServices_DE124_VeDEMD_y_P0520_EventStatus -> CPT_Dcm.DataServices_DE124_VeDEMD_y_P0520_EventStatus
    connect CPT_ComDia_Dcm_Rte_Adapter.DataServices_DE124_VeDEMD_y_P0521_EventStatus -> CPT_Dcm.DataServices_DE124_VeDEMD_y_P0521_EventStatus
    connect CPT_ComDia_Dcm_Rte_Adapter.DataServices_DE124_VeDEMD_y_P057B_EventStatus -> CPT_Dcm.DataServices_DE124_VeDEMD_y_P057B_EventStatus
    connect CPT_ComDia_Dcm_Rte_Adapter.DataServices_DE124_VeDEMD_y_P0850_EventStatus -> CPT_Dcm.DataServices_DE124_VeDEMD_y_P0850_EventStatus
    connect CPT_ComDia_Dcm_Rte_Adapter.DataServices_DE124_VeDEMD_y_P1115_EventStatus -> CPT_Dcm.DataServices_DE124_VeDEMD_y_P1115_EventStatus
    connect CPT_ComDia_Dcm_Rte_Adapter.DataServices_DE124_VeDEMD_y_P1128_EventStatus -> CPT_Dcm.DataServices_DE124_VeDEMD_y_P1128_EventStatus
    connect CPT_ComDia_Dcm_Rte_Adapter.DataServices_DE124_VeDEMD_y_P1129_EventStatus -> CPT_Dcm.DataServices_DE124_VeDEMD_y_P1129_EventStatus
    connect CPT_ComDia_Dcm_Rte_Adapter.DataServices_DE124_VeDEMD_y_P1239_EventStatus -> CPT_Dcm.DataServices_DE124_VeDEMD_y_P1239_EventStatus
    connect CPT_ComDia_Dcm_Rte_Adapter.DataServices_DE124_VeDEMD_y_P1524_EventStatus -> CPT_Dcm.DataServices_DE124_VeDEMD_y_P1524_EventStatus
    connect CPT_ComDia_Dcm_Rte_Adapter.DataServices_DE124_VeDEMD_y_P1607_EventStatus -> CPT_Dcm.DataServices_DE124_VeDEMD_y_P1607_EventStatus
    connect CPT_ComDia_Dcm_Rte_Adapter.DataServices_DE124_VeDEMD_y_P1DBD_EventStatus -> CPT_Dcm.DataServices_DE124_VeDEMD_y_P1DBD_EventStatus
    connect CPT_ComDia_Dcm_Rte_Adapter.DataServices_DE124_VeDEMD_y_P1E09_EventStatus -> CPT_Dcm.DataServices_DE124_VeDEMD_y_P1E09_EventStatus
    connect CPT_ComDia_Dcm_Rte_Adapter.DataServices_DE124_VeDEMD_y_P1E0A_EventStatus -> CPT_Dcm.DataServices_DE124_VeDEMD_y_P1E0A_EventStatus
    connect CPT_ComDia_Dcm_Rte_Adapter.DataServices_DE124_VeDEMD_y_P2066_EventStatus -> CPT_Dcm.DataServices_DE124_VeDEMD_y_P2066_EventStatus
    connect CPT_ComDia_Dcm_Rte_Adapter.DataServices_DE124_VeDEMD_y_P{2096..2099}_EventStatus -> CPT_Dcm.DataServices_DE124_VeDEMD_y_P{2096..2099}_EventStatus
    connect CPT_ComDia_Dcm_Rte_Adapter.DataServices_DE124_VeDEMD_y_P219A_EventStatus -> CPT_Dcm.DataServices_DE124_VeDEMD_y_P219A_EventStatus
    connect CPT_ComDia_Dcm_Rte_Adapter.DataServices_DE124_VeDEMD_y_P219B_EventStatus -> CPT_Dcm.DataServices_DE124_VeDEMD_y_P219B_EventStatus
    connect CPT_ComDia_Dcm_Rte_Adapter.DataServices_DE124_VeDEMD_y_P2271_EventStatus -> CPT_Dcm.DataServices_DE124_VeDEMD_y_P2271_EventStatus
    connect CPT_ComDia_Dcm_Rte_Adapter.DataServices_DE124_VeDEMD_y_P2273_EventStatus -> CPT_Dcm.DataServices_DE124_VeDEMD_y_P2273_EventStatus
    connect CPT_ComDia_Dcm_Rte_Adapter.DataServices_DE124_VeDEMD_y_P258B_EventStatus -> CPT_Dcm.DataServices_DE124_VeDEMD_y_P258B_EventStatus
    connect CPT_ComDia_Dcm_Rte_Adapter.DataServices_DE201_CAM_SYNC_STATUS_EXH_1 -> CPT_Dcm.DataServices_DE201_CAM_SYNC_STATUS_EXH_1
    connect CPT_ComDia_Dcm_Rte_Adapter.DataServices_DE201_CAM_SYNC_STATUS_INT_1 -> CPT_Dcm.DataServices_DE201_CAM_SYNC_STATUS_INT_1
    connect CPT_ComDia_Dcm_Rte_Adapter.DataServices_DE201_CAM_SYNC_STATUS_INT_2 -> CPT_Dcm.DataServices_DE201_CAM_SYNC_STATUS_INT_2
    connect CPT_ComDia_Dcm_Rte_Adapter.DataServices_DE208_CamcrksftDifIsAllNvEdgesLrnd -> CPT_Dcm.DataServices_DE208_CamcrksftDifIsAllNvEdgesLrnd
    connect CPT_ComDia_Dcm_Rte_Adapter.DataServices_DE208_SyncnSts -> CPT_Dcm.DataServices_DE208_SyncnSts
    connect CPT_ComDia_Dcm_Rte_Adapter.DataServices_DE212_ETPU_IgnFlybackPW0 -> CPT_Dcm.DataServices_DE212_ETPU_IgnFlybackPW0
    connect CPT_ComDia_Dcm_Rte_Adapter.DataServices_DE212_EngRvsRotMonrSts -> CPT_Dcm.DataServices_DE212_EngRvsRotMonrSts
    connect CPT_ComDia_Dcm_Rte_Adapter.DataServices_DE223_OxSnsrHeatrCoilU -> CPT_Dcm.DataServices_DE223_OxSnsrHeatrCoilU
    connect CPT_ComDia_Dcm_Rte_Adapter.PP_CallbackDCMRequestServices -> CPT_Dcm.CallbackDCMRequestServices_Rq0
    connect CPT_ComDia_Dcm_Rte_Adapter.PP_DcmTest_Timer -> CPT_Dcm.R_DataServices_DcmDspData_1005_0, mapping=SR_PortMapping_DcmDspData_1005_0
    connect CPT_ComScl_EngLin.PP_ComScl_RxPduInfo_AGS2_ECM_STATUS -> CPT_ComScl_EngLin_Scl.RP_ComScl_RxPduInfo_AGS2_ECM_STATUS
    connect CPT_ComScl_EngLin.PP_ComScl_RxPduInfo_AGS_ECM_STATUS -> CPT_ComScl_EngLin_Scl.RP_ComScl_RxPduInfo_AGS_ECM_STATUS
    connect CPT_ComScl_EngLin.PP_ComScl_RxPduInfo_EEV1_ECM -> CPT_ComScl_EngLin_Scl.RP_ComScl_RxPduInfo_EEV1_ECM
    connect CPT_ComScl_EngLin.PP_ComScl_RxPduInfo_EEV2_ECM -> CPT_ComScl_EngLin_Scl.RP_ComScl_RxPduInfo_EEV2_ECM
    connect CPT_ComScl_EngLin.PP_ComScl_RxPduInfo_HAPM_STAT -> CPT_ComScl_EngLin_Scl.RP_ComScl_RxPduInfo_HAPM_STAT
    connect CPT_ComScl_EngLin.PP_ComScl_RxPduInfo_HAPM_VER -> CPT_ComScl_EngLin_Scl.RP_ComScl_RxPduInfo_HAPM_VER
    connect CPT_ComScl_EngLin.PP_ComScl_RxPduInfo_LCVM2_ECM -> CPT_ComScl_EngLin_Scl.RP_ComScl_RxPduInfo_LCVM2_ECM
    connect CPT_ComScl_EngLin.PP_ComScl_RxPduInfo_LCVM_ECM -> CPT_ComScl_EngLin_Scl.RP_ComScl_RxPduInfo_LCVM_ECM
    connect CPT_ComScl_EngLin.PP_ComScl_RxPduInfo_LTRP_STAT -> CPT_ComScl_EngLin_Scl.RP_ComScl_RxPduInfo_LTRP_STAT
    connect CPT_ComScl_EngLin.PP_ComScl_RxPduInfo_LTRP_VER -> CPT_ComScl_EngLin_Scl.RP_ComScl_RxPduInfo_LTRP_VER
    connect CPT_ComScl_EngLin.PP_ComScl_RxPduInfo_PCPM_Stat -> CPT_ComScl_EngLin_Scl.RP_ComScl_RxPduInfo_PCPM_Stat
    connect CPT_ComScl_EngLin.PP_ComScl_RxPduInfo_PCPM_VER -> CPT_ComScl_EngLin_Scl.RP_ComScl_RxPduInfo_PCPM_VER
    connect CPT_ComScl_EngLin.PP_ComScl_RxPduInfo_PLA_INFO -> CPT_ComScl_EngLin_Scl.RP_ComScl_RxPduInfo_PLA_INFO
    connect CPT_ComScl_NetMtrx.PP_ComScl_RxPduInfo_ADAS_FD_HMI_FD3 -> CPT_ComScl_NetMtrx_Scl.RP_ComScl_RxPduInfo_ADAS_FD_HMI_FD3
    connect CPT_ComScl_NetMtrx.PP_ComScl_RxPduInfo_ADAS_FD_INFO2 -> CPT_ComScl_NetMtrx_Scl.RP_ComScl_RxPduInfo_ADAS_FD_INFO2
    connect CPT_ComScl_NetMtrx.PP_ComScl_RxPduInfo_ADCM_FD_A4 -> CPT_ComScl_NetMtrx_Scl.RP_ComScl_RxPduInfo_ADCM_FD_A4
    connect CPT_ComScl_NetMtrx.PP_ComScl_RxPduInfo_ASCM_FD_2 -> CPT_ComScl_NetMtrx_Scl.RP_ComScl_RxPduInfo_ASCM_FD_2
    connect CPT_ComScl_NetMtrx.PP_ComScl_RxPduInfo_BCM_FD_{10..12} -> CPT_ComScl_NetMtrx_Scl.RP_ComScl_RxPduInfo_BCM_FD_{10..12}
    connect CPT_ComScl_NetMtrx.PP_ComScl_RxPduInfo_BCM_FD_14 -> CPT_ComScl_NetMtrx_Scl.RP_ComScl_RxPduInfo_BCM_FD_14
    connect CPT_ComScl_NetMtrx.PP_ComScl_RxPduInfo_BCM_FD_23 -> CPT_ComScl_NetMtrx_Scl.RP_ComScl_RxPduInfo_BCM_FD_23
    connect CPT_ComScl_NetMtrx.PP_ComScl_RxPduInfo_BCM_FD_26 -> CPT_ComScl_NetMtrx_Scl.RP_ComScl_RxPduInfo_BCM_FD_26
    connect CPT_ComScl_NetMtrx.PP_ComScl_RxPduInfo_BCM_FD_27 -> CPT_ComScl_NetMtrx_Scl.RP_ComScl_RxPduInfo_BCM_FD_27
    connect CPT_ComScl_NetMtrx.PP_ComScl_RxPduInfo_BCM_FD_29 -> CPT_ComScl_NetMtrx_Scl.RP_ComScl_RxPduInfo_BCM_FD_29
    connect CPT_ComScl_NetMtrx.PP_ComScl_RxPduInfo_BCM_FD_3 -> CPT_ComScl_NetMtrx_Scl.RP_ComScl_RxPduInfo_BCM_FD_3
    connect CPT_ComScl_NetMtrx.PP_ComScl_RxPduInfo_BCM_FD_4 -> CPT_ComScl_NetMtrx_Scl.RP_ComScl_RxPduInfo_BCM_FD_4
    connect CPT_ComScl_NetMtrx.PP_ComScl_RxPduInfo_BCM_FD_6 -> CPT_ComScl_NetMtrx_Scl.RP_ComScl_RxPduInfo_BCM_FD_6
    connect CPT_ComScl_NetMtrx.PP_ComScl_RxPduInfo_BCM_FD_7 -> CPT_ComScl_NetMtrx_Scl.RP_ComScl_RxPduInfo_BCM_FD_7
    connect CPT_ComScl_NetMtrx.PP_ComScl_RxPduInfo_BRAKE_FD_6_FD3 -> CPT_ComScl_NetMtrx_Scl.RP_ComScl_RxPduInfo_BRAKE_FD_6_FD3
    connect CPT_ComScl_NetMtrx.PP_ComScl_RxPduInfo_CFG_DATA_CODE_REQUEST -> CPT_ComScl_NetMtrx_Scl.RP_ComScl_RxPduInfo_CFG_DATA_CODE_REQUEST
    connect CPT_ComScl_NetMtrx.PP_ComScl_RxPduInfo_CVPAM_FD_Info -> CPT_ComScl_NetMtrx_Scl.RP_ComScl_RxPduInfo_CVPAM_FD_Info
    connect CPT_ComScl_NetMtrx.PP_ComScl_RxPduInfo_DRIVETRAIN_FD_3 -> CPT_ComScl_NetMtrx_Scl.RP_ComScl_RxPduInfo_DRIVETRAIN_FD_3
    connect CPT_ComScl_NetMtrx.PP_ComScl_RxPduInfo_EPS_FD_2 -> CPT_ComScl_NetMtrx_Scl.RP_ComScl_RxPduInfo_EPS_FD_2
    connect CPT_ComScl_NetMtrx.PP_ComScl_RxPduInfo_FOTA_MASTER -> CPT_ComScl_NetMtrx_Scl.RP_ComScl_RxPduInfo_FOTA_MASTER
    connect CPT_ComScl_NetMtrx.PP_ComScl_RxPduInfo_GPF_DATA_FD_1 -> CPT_ComScl_NetMtrx_Scl.RP_ComScl_RxPduInfo_GPF_DATA_FD_1
    connect CPT_ComScl_NetMtrx.PP_ComScl_RxPduInfo_HVBATTERY{1..3} -> CPT_ComScl_NetMtrx_Scl.RP_ComScl_RxPduInfo_HVBATTERY{1..3}
    connect CPT_ComScl_NetMtrx.PP_ComScl_RxPduInfo_HVBATTERY5 -> CPT_ComScl_NetMtrx_Scl.RP_ComScl_RxPduInfo_HVBATTERY5
    connect CPT_ComScl_NetMtrx.PP_ComScl_RxPduInfo_HV_CHARGER1 -> CPT_ComScl_NetMtrx_Scl.RP_ComScl_RxPduInfo_HV_CHARGER1
    connect CPT_ComScl_NetMtrx.PP_ComScl_RxPduInfo_HYBRID_DISPLAY -> CPT_ComScl_NetMtrx_Scl.RP_ComScl_RxPduInfo_HYBRID_DISPLAY
    connect CPT_ComScl_NetMtrx.PP_ComScl_RxPduInfo_HYBRID_HVAC -> CPT_ComScl_NetMtrx_Scl.RP_ComScl_RxPduInfo_HYBRID_HVAC
    connect CPT_ComScl_NetMtrx.PP_ComScl_RxPduInfo_HYBRID_THERMAL_COMMAND -> CPT_ComScl_NetMtrx_Scl.RP_ComScl_RxPduInfo_HYBRID_THERMAL_COMMAND
    connect CPT_ComScl_NetMtrx.PP_ComScl_RxPduInfo_IBS3_DATA_1 -> CPT_ComScl_NetMtrx_Scl.RP_ComScl_RxPduInfo_IBS3_DATA_1
    connect CPT_ComScl_NetMtrx.PP_ComScl_RxPduInfo_IBS3_DATA_2 -> CPT_ComScl_NetMtrx_Scl.RP_ComScl_RxPduInfo_IBS3_DATA_2
    connect CPT_ComScl_NetMtrx.PP_ComScl_RxPduInfo_IMMO_CODE_RESPONSE -> CPT_ComScl_NetMtrx_Scl.RP_ComScl_RxPduInfo_IMMO_CODE_RESPONSE
    connect CPT_ComScl_NetMtrx.PP_ComScl_RxPduInfo_IMMO_SOP_REQUEST -> CPT_ComScl_NetMtrx_Scl.RP_ComScl_RxPduInfo_IMMO_SOP_REQUEST
    connect CPT_ComScl_NetMtrx.PP_ComScl_RxPduInfo_IMPACT_INFO -> CPT_ComScl_NetMtrx_Scl.RP_ComScl_RxPduInfo_IMPACT_INFO
    connect CPT_ComScl_NetMtrx.PP_ComScl_RxPduInfo_IPC_FD_1 -> CPT_ComScl_NetMtrx_Scl.RP_ComScl_RxPduInfo_IPC_FD_1
    connect CPT_ComScl_NetMtrx.PP_ComScl_RxPduInfo_IPC_FD_4 -> CPT_ComScl_NetMtrx_Scl.RP_ComScl_RxPduInfo_IPC_FD_4
    connect CPT_ComScl_NetMtrx.PP_ComScl_RxPduInfo_IPC_VEHICLE_SETUP -> CPT_ComScl_NetMtrx_Scl.RP_ComScl_RxPduInfo_IPC_VEHICLE_SETUP
    connect CPT_ComScl_NetMtrx.PP_ComScl_RxPduInfo_PT_SYSTEM_FD_1_FD3 -> CPT_ComScl_NetMtrx_Scl.RP_ComScl_RxPduInfo_PT_SYSTEM_FD_1_FD3
    connect CPT_ComScl_NetMtrx.PP_ComScl_RxPduInfo_RFHUB_FD_1 -> CPT_ComScl_NetMtrx_Scl.RP_ComScl_RxPduInfo_RFHUB_FD_1
    connect CPT_ComScl_NetMtrx.PP_ComScl_RxPduInfo_STEERING1 -> CPT_ComScl_NetMtrx_Scl.RP_ComScl_RxPduInfo_STEERING1
    connect CPT_ComScl_NetMtrx.PP_ComScl_RxPduInfo_TELEMATIC_FD_1 -> CPT_ComScl_NetMtrx_Scl.RP_ComScl_RxPduInfo_TELEMATIC_FD_1
    connect CPT_ComScl_NetMtrx.PP_ComScl_RxPduInfo_TELEMATIC_FD_11 -> CPT_ComScl_NetMtrx_Scl.RP_ComScl_RxPduInfo_TELEMATIC_FD_11
    connect CPT_ComScl_NetMtrx.PP_ComScl_RxPduInfo_TELEMATIC_FD_14 -> CPT_ComScl_NetMtrx_Scl.RP_ComScl_RxPduInfo_TELEMATIC_FD_14
    connect CPT_ComScl_NetMtrx.PP_ComScl_RxPduInfo_TELEMATIC_FD_5 -> CPT_ComScl_NetMtrx_Scl.RP_ComScl_RxPduInfo_TELEMATIC_FD_5
    connect CPT_ComScl_NetMtrx.PP_ComScl_RxPduInfo_VSIM_FD_1 -> CPT_ComScl_NetMtrx_Scl.RP_ComScl_RxPduInfo_VSIM_FD_1
    connect CPT_ComScl_NetMtrx.PP_ComScl_RxSigGrpInfo_IMMO_CODE_RESPONSE_Pkt -> CPT_ComScl_NetMtrx_Scl.RP_ComScl_RxSigGrpInfo_IMMO_CODE_RESPONSE_Pkt
    connect CPT_ComScl_NetMtrx2.PP_ComScl_RxPduInfo_ADAS_FD_HMI_FD14 -> CPT_ComScl_NetMtrx2_Scl.RP_ComScl_RxPduInfo_ADAS_FD_HMI_FD14
    connect CPT_ComScl_NetMtrx2.PP_ComScl_RxPduInfo_BRAKE_FD_1_FD14 -> CPT_ComScl_NetMtrx2_Scl.RP_ComScl_RxPduInfo_BRAKE_FD_1_FD14
    connect CPT_ComScl_NetMtrx2.PP_ComScl_RxPduInfo_HYBRID_POWERTRAIN1_FD14 -> CPT_ComScl_NetMtrx2_Scl.RP_ComScl_RxPduInfo_HYBRID_POWERTRAIN1_FD14
    connect CPT_ComScl_NetMtrx3.PP_ComScl_RxPduInfo_HYBRID_THERMAL_COMMAND_FD16 -> CPT_ComScl_NetMtrx3_Scl.RP_ComScl_RxPduInfo_HYBRID_THERMAL_COMMAND_FD16
    connect CPT_ComScl_NetMtrx_Scl.VeCANR_d_IgnitionOnCounter_FD3 -> IoSigIfAdapt_SwSStellantis.VeCANR_d_IgnitionOnCounter_FD3
    connect CPT_ESC_EveCfg.PP_ESC_EveCfg -> CPT_ESC_EveCfg.RP_ESC_EveCfg
    connect CPT_ESC_EveCfg.PP_stMinSyncAgEveGen -> CPT_ESC_OsTskActvnHndlr.RP_stMinSyncAgEveGen, variation-point={short-label=VP_AssemblySwConnector_VP_ESC_NRAGEVEWCYC_SC_NEQ_0_AND_ESC_NRTSKAGEVE_SC_NEQ_0, sw-syscond=( ( /RB/PT/Common/SwSystemconsts/Adjustables/ESC_NRAGEVEWCYC_SC !=0&& /RB/PT/Common/SwSystemconsts/Adjustables/ESC_NRTSKAGEVE_SC !=0 ) )&&( /RB/PT/Common/SwSystemconsts/Adjustables/ESC_NRAGEVEWCYC_SC !=0&& /RB/PT/Common/SwSystemconsts/Adjustables/ESC_NRTSKAGEVE_SC !=0 )}
    connect CPT_ESC_HwIntrptEveGen.PP_ESC_HwIntrptEveGen -> CPT_ESC_EveCfg.RP_ESC_HwIntrptEveGen
    connect CPT_ESC_Ladp.PP_Eep_EnvRamInvld -> CPT_esc_tasklink.RP_Eep_EnvRamInvld, variation-point={short-label=VP_ASC_CPT_ESC_Ladp_PP_Eep_EnvRamInvld_CPT_esc_tasklink_RP_Eep_EnvRamInvld_ESC_SWTSYNRTMEASMT_SC_EQ_1_ESC_SWTSYNRTMEASMT_SC_EQ_1, sw-syscond=( ( ( /RB/PT/Common/SwSystemconsts/Adjustables/ESC_SWTSYNRTMEASMT_SC ==1) )&&( ( /RB/PT/Common/SwSystemconsts/Adjustables/ESC_SWTSYNRTMEASMT_SC ==1) ) )&&( ( /RB/PT/Common/SwSystemconsts/Adjustables/ESC_SWTSYNRTMEASMT_SC ==1) )&&( ( /RB/PT/Common/SwSystemconsts/Adjustables/ESC_SWTSYNRTMEASMT_SC ==1) )}
    connect CPT_ESC_OsTskActvnHndlr.PP_ESC_OsTskActvnHndlr -> CPT_ESC_EveCfg.RP_ESC_OsTskActvnHndlr
    connect CPT_ESC_OsTskActvnHndlr.PP_ESC_OsTskActvnHndlr -> CPT_ESC_OsTskActvnHndlr.RP_ESC_OsTskActvnHndlr
    connect CPT_ESC_OsTskActvnHndlr.PP_ESC_OsTskActvnHndlr_AgEveE0_TRIGSRC -> CPT_ESC_OsTskActvnHndlr.RP_ESC_OsTskActvnHndlr_AgEveE0_TRIGSRC, variation-point={short-label=VP_AssemblySwConnector_VP_ESC_NRAGEVEWCYC_SC_NEQ_0_AND_ESC_NRTSKAGEVE_SC_NEQ_0_VP_ESC_NRAGEVEWCYC_SC_NEQ_0_AND_ESC_NRTSKAGEVE_SC, sw-syscond=( ( /RB/PT/Common/SwSystemconsts/Adjustables/ESC_NRAGEVEWCYC_SC !=0&& /RB/PT/Common/SwSystemconsts/Adjustables/ESC_NRTSKAGEVE_SC !=0 )&&( /RB/PT/Common/SwSystemconsts/Adjustables/ESC_NRAGEVEWCYC_SC !=0&& /RB/PT/Common/SwSystemconsts/Adjustables/ESC_NRTSKAGEVE_SC !=0 ) )&&( /RB/PT/Common/SwSystemconsts/Adjustables/ESC_NRAGEVEWCYC_SC !=0&& /RB/PT/Common/SwSystemconsts/Adjustables/ESC_NRTSKAGEVE_SC !=0 )&&( /RB/PT/Common/SwSystemconsts/Adjustables/ESC_NRAGEVEWCYC_SC !=0&& /RB/PT/Common/SwSystemconsts/Adjustables/ESC_NRTSKAGEVE_SC !=0 )}
    connect CPT_ESC_OsTskActvnHndlr.PP_ESC_OsTskActvnHndlr_AgEveE0_TRIGSRC -> Epm_SwSStellantis.RP_ESC_OsTskActvnHndlr_AgEveE0_Epm_TRIGSRC, variation-point={short-label=VP_AssemblySwConnector_VP_ESC_NRAGEVEWCYC_SC_NEQ_0_AND_ESC_NRTSKAGEVE_SC_NEQ_0, sw-syscond=( ( /RB/PT/Common/SwSystemconsts/Adjustables/ESC_NRAGEVEWCYC_SC !=0&& /RB/PT/Common/SwSystemconsts/Adjustables/ESC_NRTSKAGEVE_SC !=0 ) )&&( /RB/PT/Common/SwSystemconsts/Adjustables/ESC_NRAGEVEWCYC_SC !=0&& /RB/PT/Common/SwSystemconsts/Adjustables/ESC_NRTSKAGEVE_SC !=0 )}
    connect CPT_ESC_OsTskActvnHndlr.PP_ESC_OsTskActvnHndlr_AgEveE1_TRIGSRC -> CPT_ESC_OsTskActvnHndlr.RP_ESC_OsTskActvnHndlr_AgEveE1_TRIGSRC, variation-point={short-label=VP_AssemblySwConnector_VP_ESC_NRAGEVEWCYC_SC_NEQ_0_AND_ESC_NRTSKAGEVE_SC_EQ_2_VP_ESC_NRAGEVEWCYC_SC_NEQ_0_AND_ESC_NRTSKAGEVE_SC, sw-syscond=( ( /RB/PT/Common/SwSystemconsts/Adjustables/ESC_NRAGEVEWCYC_SC !=0&& /RB/PT/Common/SwSystemconsts/Adjustables/ESC_NRTSKAGEVE_SC >=2 )&&( /RB/PT/Common/SwSystemconsts/Adjustables/ESC_NRAGEVEWCYC_SC !=0&& /RB/PT/Common/SwSystemconsts/Adjustables/ESC_NRTSKAGEVE_SC >=2 ) )&&( /RB/PT/Common/SwSystemconsts/Adjustables/ESC_NRAGEVEWCYC_SC !=0&& /RB/PT/Common/SwSystemconsts/Adjustables/ESC_NRTSKAGEVE_SC >=2 )&&( /RB/PT/Common/SwSystemconsts/Adjustables/ESC_NRAGEVEWCYC_SC !=0&& /RB/PT/Common/SwSystemconsts/Adjustables/ESC_NRTSKAGEVE_SC >=2 )}
    connect CPT_ESC_OsTskActvnHndlr.PP_ESC_OsTskActvnHndlr_AgEveE1_TRIGSRC -> Epm_SwSStellantis.RP_ESC_OsTskActvnHndlr_AgEveE1_Epm_TRIGSRC, variation-point={short-label=VP_AssemblySwConnector_VP_ESC_NRAGEVEWCYC_SC_NEQ_0_AND_ESC_NRTSKAGEVE_SC_EQ_2, sw-syscond=( ( /RB/PT/Common/SwSystemconsts/Adjustables/ESC_NRAGEVEWCYC_SC !=0&& /RB/PT/Common/SwSystemconsts/Adjustables/ESC_NRTSKAGEVE_SC >=2 ) )&&( /RB/PT/Common/SwSystemconsts/Adjustables/ESC_NRAGEVEWCYC_SC !=0&& /RB/PT/Common/SwSystemconsts/Adjustables/ESC_NRTSKAGEVE_SC >=2 )}
    connect CPT_ESC_OsTskActvnHndlr.PP_ESC_OsTskActvnHndlr_AgEveE2_TRIGSRC -> CPT_ESC_OsTskActvnHndlr.RP_ESC_OsTskActvnHndlr_AgEveE2_TRIGSRC, variation-point={short-label=VP_AssemblySwConnector_VP_ESC_NRAGEVEWCYC_SC_NEQ_0_AND_ESC_NRTSKAGEVE_SC_EQ_3_VP_ESC_NRAGEVEWCYC_SC_NEQ_0_AND_ESC_NRTSKAGEVE_SC, sw-syscond=( ( /RB/PT/Common/SwSystemconsts/Adjustables/ESC_NRAGEVEWCYC_SC !=0&& /RB/PT/Common/SwSystemconsts/Adjustables/ESC_NRTSKAGEVE_SC ==3 )&&( /RB/PT/Common/SwSystemconsts/Adjustables/ESC_NRAGEVEWCYC_SC !=0&& /RB/PT/Common/SwSystemconsts/Adjustables/ESC_NRTSKAGEVE_SC ==3 ) )&&( /RB/PT/Common/SwSystemconsts/Adjustables/ESC_NRAGEVEWCYC_SC !=0&& /RB/PT/Common/SwSystemconsts/Adjustables/ESC_NRTSKAGEVE_SC ==3 )&&( /RB/PT/Common/SwSystemconsts/Adjustables/ESC_NRAGEVEWCYC_SC !=0&& /RB/PT/Common/SwSystemconsts/Adjustables/ESC_NRTSKAGEVE_SC ==3 )}
    connect CPT_ESC_OsTskActvnHndlr.PP_ESC_OsTskActvnHndlr_AgEveE2_TRIGSRC -> Epm_SwSStellantis.RP_ESC_OsTskActvnHndlr_AgEveE2_Epm_TRIGSRC, variation-point={short-label=VP_AssemblySwConnector_VP_ESC_NRAGEVEWCYC_SC_NEQ_0_AND_ESC_NRTSKAGEVE_SC_EQ_3, sw-syscond=( ( /RB/PT/Common/SwSystemconsts/Adjustables/ESC_NRAGEVEWCYC_SC !=0&& /RB/PT/Common/SwSystemconsts/Adjustables/ESC_NRTSKAGEVE_SC ==3 ) )&&( /RB/PT/Common/SwSystemconsts/Adjustables/ESC_NRAGEVEWCYC_SC !=0&& /RB/PT/Common/SwSystemconsts/Adjustables/ESC_NRTSKAGEVE_SC ==3 )}
    connect CPT_Epm_Ladp.PP_EpmCaS_numSegSerLst -> CPT_ESC_OsTskActvnHndlr.RP_EpmCaS_numSegSerLst, variation-point={short-label=VP_AssemblySwConnector_VP_ESC_SELNCAMSFTTSKACTVN_SC_EQ_1_AND_ESC_SELNCAMSFTSYNCN_SC_NEQ_DISABLE, sw-syscond=( ( /RB/PT/Common/SwSystemconsts/Adjustables/ESC_SELNCAMSFTTSKACTVN_SC ==1&& /RB/PT/Common/SwSystemconsts/Adjustables/ESC_SELNCAMSFTSYNCN_SC !=255 ) )&&( /RB/PT/Common/SwSystemconsts/Adjustables/ESC_SELNCAMSFTTSKACTVN_SC ==1&& /RB/PT/Common/SwSystemconsts/Adjustables/ESC_SELNCAMSFTSYNCN_SC !=255 )}
    connect CPT_Epm_Ladp.PP_EpmCrS_tiSeg -> CPT_esc_stack.RP_EpmCrS_tiSeg, variation-point={short-label=VP_ASC_CPT_Epm_Ladp_PP_EpmCrS_tiSeg_CPT_esc_stack_RP_EpmCrS_tiSeg_ESC_SYNCTASK_SC_NOT_EQ_1_ESC_SYNCTASK_SC_NEQ_1, sw-syscond=( ( ( /RB/PT/Common/SwSystemconsts/Adjustables/ESC_SYNCTASK_SC != 1) )&&( ( /RB/PT/Common/SwSystemconsts/Adjustables/ESC_SYNCTASK_SC != 1) ) )&&( ( /RB/PT/Common/SwSystemconsts/Adjustables/ESC_SYNCTASK_SC != 1) )&&( ( /RB/PT/Common/SwSystemconsts/Adjustables/ESC_SYNCTASK_SC != 1) )}
    connect CPT_Epm_Ladp.PP_EpmCrS_tiSegCurr -> CPT_esc_stack.RP_EpmCrS_tiSegCurr, variation-point={short-label=VP_ASC_CPT_Epm_Ladp_PP_EpmCrS_tiSegCurr_CPT_esc_stack_RP_EpmCrS_tiSegCurr_ESC_SYNCTASK_SC_NOT_EQ_1_ESC_SYNCTASK_SC_NEQ_1, sw-syscond=( ( ( /RB/PT/Common/SwSystemconsts/Adjustables/ESC_SYNCTASK_SC != 1) )&&( ( /RB/PT/Common/SwSystemconsts/Adjustables/ESC_SYNCTASK_SC != 1) ) )&&( ( /RB/PT/Common/SwSystemconsts/Adjustables/ESC_SYNCTASK_SC != 1) )&&( ( /RB/PT/Common/SwSystemconsts/Adjustables/ESC_SYNCTASK_SC != 1) )}
    connect CPT_Epm_Ladp.PP_EpmSeq_numInt -> CPT_ESC_EveCfg.RP_EpmSeq_numInt
    connect CPT_Epm_Ladp.PP_EpmSeq_numInt -> CPT_esc_tasklink.RP_EpmSeq_numInt
    connect CPT_Epm_Ladp.PP_EpmSyn_phiInt -> CPT_ESC_EveCfg.RP_EpmSyn_phiInt, variation-point={short-label=VP_AssemblySwConnector_ESC_SWTSYNRTMEASMT_SC_EQ_1_OR_ESC_NRTSKAGEVE_SC_GREATER_1, sw-syscond=( ( /RB/PT/Common/SwSystemconsts/Adjustables/ESC_SWTSYNRTMEASMT_SC ==1|| /RB/PT/Common/SwSystemconsts/Adjustables/ESC_NRTSKAGEVE_SC !=0 ) )&&( /RB/PT/Common/SwSystemconsts/Adjustables/ESC_SWTSYNRTMEASMT_SC==1|| /RB/PT/Common/SwSystemconsts/Adjustables/ESC_NRTSKAGEVE_SC!=0 )}
    connect CPT_Epm_Ladp.PP_EpmSyn_phiInt -> CPT_esc_tasklink.RP_EpmSyn_phiInt, variation-point={short-label=VP_ASC_CPT_Epm_Ladp_PP_EpmSyn_phiInt_CPT_esc_tasklink_RP_EpmSyn_phiInt_ESC_SWTSYNRTMEASMT_SC_EQ_1_OR_ESC_NRTSKAGEVE_SC_GREATER_1, sw-syscond=( ( ( /RB/PT/Common/SwSystemconsts/Adjustables/ESC_SWTSYNRTMEASMT_SC ==1) )&&( ( /RB/PT/Common/SwSystemconsts/Adjustables/ESC_SWTSYNRTMEASMT_SC ==1) ) )&&( /RB/PT/Common/SwSystemconsts/Adjustables/ESC_SWTSYNRTMEASMT_SC==1|| /RB/PT/Common/SwSystemconsts/Adjustables/ESC_NRTSKAGEVE_SC!=0 )&&( ( /RB/PT/Common/SwSystemconsts/Adjustables/ESC_SWTSYNRTMEASMT_SC ==1) )}
    connect CPT_Epm_Ladp.PP_Epm_nEng -> CPT_ESC_EveCfg.RP_Epm_nEng, variation-point={short-label=VP_AssemblySwConnector_ESC_NRTSKAGEVE_SC_NEQ_0_OR_ESC_SELNCAMSFTTSKACTVN_SC_EQ_1_AND_ESC_SELNCAMSFTSYNCN_SC_NOT_EQ_255, sw-syscond=( ( ((( /RB/PT/Common/SwSystemconsts/Adjustables/ESC_SELNCAMSFTTSKACTVN_SC ==1) && ( /RB/PT/Common/SwSystemconsts/Adjustables/ESC_SELNCAMSFTSYNCN_SC != 255))||( /RB/PT/Common/SwSystemconsts/Adjustables/ESC_NRTSKAGEVE_SC !=0)) ) )&&( ((( /RB/PT/Common/SwSystemconsts/Adjustables/ESC_SELNCAMSFTTSKACTVN_SC ==1) && ( /RB/PT/Common/SwSystemconsts/Adjustables/ESC_SELNCAMSFTSYNCN_SC != 255))||( /RB/PT/Common/SwSystemconsts/Adjustables/ESC_NRTSKAGEVE_SC !=0)) )}
    connect CPT_Epm_Ladp.PP_Epm_nEng -> CPT_ESC_OsTskActvnHndlr.RP_Epm_nEng, variation-point={short-label=VP_AssemblySwConnector_ESC_NRTSKAGEVE_SC_NEQ_0_OR_ESC_SELNCAMSFTTSKACTVN_SC_EQ_1_AND_ESC_SELNCAMSFTSYNCN_SC_NOT_EQ_255_VP_ESC_SE, sw-syscond=( ( ((( /RB/PT/Common/SwSystemconsts/Adjustables/ESC_SELNCAMSFTTSKACTVN_SC ==1) && ( /RB/PT/Common/SwSystemconsts/Adjustables/ESC_SELNCAMSFTSYNCN_SC != 255))||( /RB/PT/Common/SwSystemconsts/Adjustables/ESC_NRTSKAGEVE_SC !=0)) )&&( /RB/PT/Common/SwSystemconsts/Adjustables/ESC_SELNCAMSFTTSKACTVN_SC ==1&& /RB/PT/Common/SwSystemconsts/Adjustables/ESC_SELNCAMSFTSYNCN_SC !=255 ) )&&( ((( /RB/PT/Common/SwSystemconsts/Adjustables/ESC_SELNCAMSFTTSKACTVN_SC ==1) && ( /RB/PT/Common/SwSystemconsts/Adjustables/ESC_SELNCAMSFTSYNCN_SC != 255))||( /RB/PT/Common/SwSystemconsts/Adjustables/ESC_NRTSKAGEVE_SC !=0)) )&&( /RB/PT/Common/SwSystemconsts/Adjustables/ESC_SELNCAMSFTTSKACTVN_SC ==1&& /RB/PT/Common/SwSystemconsts/Adjustables/ESC_SELNCAMSFTSYNCN_SC !=255 )}
    connect CPT_Epm_Ladp.PP_Epm_phiCyl -> CPT_esc_tasklink.RP_Epm_phiCyl, variation-point={short-label=VP_ASC_CPT_Epm_Ladp_PP_Epm_phiCyl_CPT_esc_tasklink_RP_Epm_phiCyl_ESC_SWTSYNRTMEASMT_SC_EQ_1_ESC_SWTSYNRTMEASMT_SC_EQ_1_AND_CMBTY, sw-syscond=( ( ( /RB/PT/Common/SwSystemconsts/Adjustables/ESC_SWTSYNRTMEASMT_SC ==1) )&&( (( /RB/PT/Common/SwSystemconsts/Adjustables/ESC_SWTSYNRTMEASMT_SC ==1) && ( /RB/PT/Common/SwSystemconsts/Adjustables/CMBTYP_SY == /RB/PT/esc_tasklink/SwSystemconsts/CMBTYP_DS )) ) )&&( ( /RB/PT/Common/SwSystemconsts/Adjustables/ESC_SWTSYNRTMEASMT_SC ==1) )&&( (( /RB/PT/Common/SwSystemconsts/Adjustables/ESC_SWTSYNRTMEASMT_SC ==1) && ( /RB/PT/Common/SwSystemconsts/Adjustables/CMBTYP_SY == /RB/PT/ESC/SwSystemconsts/CMBTYP_DS )) )}
    connect CPT_Epm_Ladp.PP_Epm_stSync -> CPT_ESC_EveCfg.RP_Epm_stSync, variation-point={short-label=VP_AssemblySwConnector_ESC_NRTSKAGEVE_SC_NEQ_0_OR_ESC_SELNCAMSFTTSKACTVN_SC_EQ_1, sw-syscond=( ( (( /RB/PT/Common/SwSystemconsts/Adjustables/ESC_SELNCAMSFTTSKACTVN_SC ==1)||( /RB/PT/Common/SwSystemconsts/Adjustables/ESC_NRTSKAGEVE_SC !=0)) ) )&&( (( /RB/PT/Common/SwSystemconsts/Adjustables/ESC_SELNCAMSFTTSKACTVN_SC ==1)||( /RB/PT/Common/SwSystemconsts/Adjustables/ESC_NRTSKAGEVE_SC !=0)) )}
    connect CPT_SysC_Ladp.PP_SyC_stSub -> CPT_esc_tasklink.RP_SyC_stSub
    connect CPT_SysC_Ladp.PP_SyC_tiDrv -> CPT_esc_tasklink.RP_SyC_tiDrv
    connect CPT_esc_stack.PP_ESC_PushSampTime -> CPT_esc_stack.RP_ESC_PushSampTime, variation-point={short-label=VP_ASC_CPT_esc_stack_PP_ESC_PushSampTime_CPT_esc_stack_RP_ESC_PushSampTime_ESC_SYNCTASK_SC_NEQ_1_ESC_SYNCTASK_SC_NEQ_1, sw-syscond=( ( ( /RB/PT/Common/SwSystemconsts/Adjustables/ESC_SYNCTASK_SC != 1) )&&( ( /RB/PT/Common/SwSystemconsts/Adjustables/ESC_SYNCTASK_SC != 1) ) )&&( ( /RB/PT/Common/SwSystemconsts/Adjustables/ESC_SYNCTASK_SC != 1) )&&( ( /RB/PT/Common/SwSystemconsts/Adjustables/ESC_SYNCTASK_SC != 1) )}
    connect CPT_esc_stack.PP_ESC_Stack -> CPT_esc_stack.RP_ESC_Stack, variation-point={short-label=VP_ASC_CPT_esc_stack_PP_ESC_Stack_CPT_esc_stack_RP_ESC_Stack_ESC_SYNCTASK_SC_NEQ_1_ESC_SYNCTASK_SC_NEQ_1, sw-syscond=( ( ( /RB/PT/Common/SwSystemconsts/Adjustables/ESC_SYNCTASK_SC != 1) )&&( ( /RB/PT/Common/SwSystemconsts/Adjustables/ESC_SYNCTASK_SC != 1) ) )&&( ( /RB/PT/Common/SwSystemconsts/Adjustables/ESC_SYNCTASK_SC != 1) )&&( ( /RB/PT/Common/SwSystemconsts/Adjustables/ESC_SYNCTASK_SC != 1) )}
    connect CPT_esc_stack.PP_ESC_agEveE0TskStrt -> CPT_ESC_OsTskActvnHndlr.RP_agEveE0TskStrt, mapping=PIM_IF_agEveE0TskStrt_IF_ESC_agEveE0TskStrt, variation-point={short-label=VP_AssemblySwConnector_ESC_NRAGEVEWCYC_SC_NEQ_0_AND_ESC_NRTSKAGEVE_SC_NEQ_0_VP_ESC_NRAGEVEWCYC_SC_NEQ_0_AND_ESC_NRTSKAGEVE_SC_NE, sw-syscond=( ( (( /RB/PT/Common/SwSystemconsts/Adjustables/ESC_NRAGEVEWCYC_SC !=0) && ( /RB/PT/Common/SwSystemconsts/Adjustables/ESC_NRTSKAGEVE_SC !=0)) )&&( /RB/PT/Common/SwSystemconsts/Adjustables/ESC_NRAGEVEWCYC_SC !=0&& /RB/PT/Common/SwSystemconsts/Adjustables/ESC_NRTSKAGEVE_SC !=0 ) )&&( (( /RB/PT/Common/SwSystemconsts/Adjustables/ESC_NRAGEVEWCYC_SC !=0) && ( /RB/PT/Common/SwSystemconsts/Adjustables/ESC_NRTSKAGEVE_SC !=0)) )&&( /RB/PT/Common/SwSystemconsts/Adjustables/ESC_NRAGEVEWCYC_SC !=0&& /RB/PT/Common/SwSystemconsts/Adjustables/ESC_NRTSKAGEVE_SC !=0 )}
    connect CPT_esc_stack.PP_ESC_agEveE1TskStrt -> CPT_ESC_OsTskActvnHndlr.RP_agEveE1TskStrt, mapping=PIM_IF_agEveE1TskStrt_IF_ESC_agEveE1TskStrt, variation-point={short-label=VP_AssemblySwConnector_ESC_NRAGEVEWCYC_SC_NEQ_0_AND_ESC_NRTSKAGEVE_SC_GEQ_2_VP_ESC_NRAGEVEWCYC_SC_NEQ_0_AND_ESC_NRTSKAGEVE_SC_EQ, sw-syscond=( ( (( /RB/PT/Common/SwSystemconsts/Adjustables/ESC_NRAGEVEWCYC_SC !=0) && ( /RB/PT/Common/SwSystemconsts/Adjustables/ESC_NRTSKAGEVE_SC >=2)) )&&( /RB/PT/Common/SwSystemconsts/Adjustables/ESC_NRAGEVEWCYC_SC !=0&& /RB/PT/Common/SwSystemconsts/Adjustables/ESC_NRTSKAGEVE_SC >=2 ) )&&( (( /RB/PT/Common/SwSystemconsts/Adjustables/ESC_NRAGEVEWCYC_SC !=0) && ( /RB/PT/Common/SwSystemconsts/Adjustables/ESC_NRTSKAGEVE_SC >=2)) )&&( /RB/PT/Common/SwSystemconsts/Adjustables/ESC_NRAGEVEWCYC_SC !=0&& /RB/PT/Common/SwSystemconsts/Adjustables/ESC_NRTSKAGEVE_SC >=2 )}
    connect CPT_esc_stack.PP_ESC_agEveE2TskStrt -> CPT_ESC_OsTskActvnHndlr.RP_agEveE2TskStrt, mapping=PIM_IF_agEveE2TskStrt_IF_ESC_agEveE2TskStrt, variation-point={short-label=VP_AssemblySwConnector_ESC_NRAGEVEWCYC_SC_NEQ_0_AND_ESC_NRTSKAGEVE_SC_EQ_3_VP_ESC_NRAGEVEWCYC_SC_NEQ_0_AND_ESC_NRTSKAGEVE_SC_EQ, sw-syscond=( ( (( /RB/PT/Common/SwSystemconsts/Adjustables/ESC_NRAGEVEWCYC_SC !=0) && ( /RB/PT/Common/SwSystemconsts/Adjustables/ESC_NRTSKAGEVE_SC ==3)) )&&( /RB/PT/Common/SwSystemconsts/Adjustables/ESC_NRAGEVEWCYC_SC !=0&& /RB/PT/Common/SwSystemconsts/Adjustables/ESC_NRTSKAGEVE_SC ==3 ) )&&( (( /RB/PT/Common/SwSystemconsts/Adjustables/ESC_NRAGEVEWCYC_SC !=0) && ( /RB/PT/Common/SwSystemconsts/Adjustables/ESC_NRTSKAGEVE_SC ==3)) )&&( /RB/PT/Common/SwSystemconsts/Adjustables/ESC_NRAGEVEWCYC_SC !=0&& /RB/PT/Common/SwSystemconsts/Adjustables/ESC_NRTSKAGEVE_SC ==3 )}
    connect CPT_esc_stack.PP_ESC_idCurrRunngAgEveTsk -> CPT_ESC_OsTskActvnHndlr.RP_idCurrRunngAgEveTsk, mapping=PIM_IF_idCurrRunngAgEveTsk_IF_ESC_idCurrRunngAgEveTsk, variation-point={short-label=VP_AssemblySwConnector_ESC_NRAGEVEWCYC_SC_NEQ_0_AND_ESC_NRTSKAGEVE_SC_NEQ_0_VP_ESC_NRAGEVEWCYC_SC_NEQ_0_AND_ESC_NRTSKAGEVE_SC_NE, sw-syscond=( ( (( /RB/PT/Common/SwSystemconsts/Adjustables/ESC_NRAGEVEWCYC_SC !=0) && ( /RB/PT/Common/SwSystemconsts/Adjustables/ESC_NRTSKAGEVE_SC !=0)) )&&( /RB/PT/Common/SwSystemconsts/Adjustables/ESC_NRAGEVEWCYC_SC !=0&& /RB/PT/Common/SwSystemconsts/Adjustables/ESC_NRTSKAGEVE_SC !=0 ) )&&( (( /RB/PT/Common/SwSystemconsts/Adjustables/ESC_NRAGEVEWCYC_SC !=0) && ( /RB/PT/Common/SwSystemconsts/Adjustables/ESC_NRTSKAGEVE_SC !=0)) )&&( /RB/PT/Common/SwSystemconsts/Adjustables/ESC_NRAGEVEWCYC_SC !=0&& /RB/PT/Common/SwSystemconsts/Adjustables/ESC_NRTSKAGEVE_SC !=0 )}
    connect CPT_esc_stack.PP_ESC_tiAgEveE0TskStrt -> CPT_ESC_OsTskActvnHndlr.RP_tiAgEveE0TskStrt, mapping=PIM_IF_tiAgEveE0TskStrt_IF_ESC_tiAgEveE0TskStrt, variation-point={short-label=VP_AssemblySwConnector_ESC_NRAGEVEWCYC_SC_NEQ_0_AND_ESC_NRTSKAGEVE_SC_NEQ_0_VP_ESC_NRAGEVEWCYC_SC_NEQ_0_AND_ESC_NRTSKAGEVE_SC_NE, sw-syscond=( ( (( /RB/PT/Common/SwSystemconsts/Adjustables/ESC_NRAGEVEWCYC_SC !=0) && ( /RB/PT/Common/SwSystemconsts/Adjustables/ESC_NRTSKAGEVE_SC !=0)) )&&( /RB/PT/Common/SwSystemconsts/Adjustables/ESC_NRAGEVEWCYC_SC !=0&& /RB/PT/Common/SwSystemconsts/Adjustables/ESC_NRTSKAGEVE_SC !=0 ) )&&( (( /RB/PT/Common/SwSystemconsts/Adjustables/ESC_NRAGEVEWCYC_SC !=0) && ( /RB/PT/Common/SwSystemconsts/Adjustables/ESC_NRTSKAGEVE_SC !=0)) )&&( /RB/PT/Common/SwSystemconsts/Adjustables/ESC_NRAGEVEWCYC_SC !=0&& /RB/PT/Common/SwSystemconsts/Adjustables/ESC_NRTSKAGEVE_SC !=0 )}
    connect CPT_esc_stack.PP_ESC_tiAgEveE1TskStrt -> CPT_ESC_OsTskActvnHndlr.RP_tiAgEveE1TskStrt, mapping=PIM_IF_tiAgEveE1TskStrt_IF_ESC_tiAgEveE1TskStrt, variation-point={short-label=VP_AssemblySwConnector_ESC_NRAGEVEWCYC_SC_NEQ_0_AND_ESC_NRTSKAGEVE_SC_GEQ_2_VP_ESC_NRAGEVEWCYC_SC_NEQ_0_AND_ESC_NRTSKAGEVE_SC_EQ, sw-syscond=( ( (( /RB/PT/Common/SwSystemconsts/Adjustables/ESC_NRAGEVEWCYC_SC !=0) && ( /RB/PT/Common/SwSystemconsts/Adjustables/ESC_NRTSKAGEVE_SC >=2)) )&&( /RB/PT/Common/SwSystemconsts/Adjustables/ESC_NRAGEVEWCYC_SC !=0&& /RB/PT/Common/SwSystemconsts/Adjustables/ESC_NRTSKAGEVE_SC >=2 ) )&&( (( /RB/PT/Common/SwSystemconsts/Adjustables/ESC_NRAGEVEWCYC_SC !=0) && ( /RB/PT/Common/SwSystemconsts/Adjustables/ESC_NRTSKAGEVE_SC >=2)) )&&( /RB/PT/Common/SwSystemconsts/Adjustables/ESC_NRAGEVEWCYC_SC !=0&& /RB/PT/Common/SwSystemconsts/Adjustables/ESC_NRTSKAGEVE_SC >=2 )}
    connect CPT_esc_stack.PP_ESC_tiAgEveE2TskStrt -> CPT_ESC_OsTskActvnHndlr.RP_tiAgEveE2TskStrt, mapping=PIM_IF_tiAgEveE2TskStrt_IF_ESC_tiAgEveE2TskStrt, variation-point={short-label=VP_AssemblySwConnector_ESC_NRAGEVEWCYC_SC_NEQ_0_AND_ESC_NRTSKAGEVE_SC_EQ_3_VP_ESC_NRAGEVEWCYC_SC_NEQ_0_AND_ESC_NRTSKAGEVE_SC_EQ, sw-syscond=( ( (( /RB/PT/Common/SwSystemconsts/Adjustables/ESC_NRAGEVEWCYC_SC !=0) && ( /RB/PT/Common/SwSystemconsts/Adjustables/ESC_NRTSKAGEVE_SC ==3)) )&&( /RB/PT/Common/SwSystemconsts/Adjustables/ESC_NRAGEVEWCYC_SC !=0&& /RB/PT/Common/SwSystemconsts/Adjustables/ESC_NRTSKAGEVE_SC ==3 ) )&&( (( /RB/PT/Common/SwSystemconsts/Adjustables/ESC_NRAGEVEWCYC_SC !=0) && ( /RB/PT/Common/SwSystemconsts/Adjustables/ESC_NRTSKAGEVE_SC ==3)) )&&( /RB/PT/Common/SwSystemconsts/Adjustables/ESC_NRAGEVEWCYC_SC !=0&& /RB/PT/Common/SwSystemconsts/Adjustables/ESC_NRTSKAGEVE_SC ==3 )}
    connect CPT_esc_stack.PP_rbm_ESC_tiSampling -> CPT_ESC_Ladp.RP_rbm_ESC_tiSampling
    connect CPT_esc_stack.PP_rbm_ESC_tiSampling_s -> CPT_ESC_Ladp.RP_rbm_ESC_tiSampling_s
    connect CPT_esc_tasklink.PP_ESC_Tasklink -> CPT_esc_tasklink.RP_ESC_Tasklink, variation-point={short-label=VP_ASC_CPT_esc_tasklink_PP_ESC_Tasklink_CPT_esc_tasklink_RP_ESC_Tasklink_ESC_SWTSYNRTMEASMT_SC_EQ_1_ESC_SWTSYNRTMEASMT_SC_EQ_1, sw-syscond=( ( ( /RB/PT/Common/SwSystemconsts/Adjustables/ESC_SWTSYNRTMEASMT_SC ==1) )&&( ( /RB/PT/Common/SwSystemconsts/Adjustables/ESC_SWTSYNRTMEASMT_SC ==1) ) )&&( ( /RB/PT/Common/SwSystemconsts/Adjustables/ESC_SWTSYNRTMEASMT_SC ==1) )&&( ( /RB/PT/Common/SwSystemconsts/Adjustables/ESC_SWTSYNRTMEASMT_SC ==1) )}
    connect CPT_esc_tasklink.PP_ESC_Tasklink_EpmNoSync_TRIGSRC -> CPT_esc_tasklink.RP_ESC_Tasklink_EpmNoSync_TRIGSRC
    connect CPT_esc_tasklink.PP_ESC_Tasklink_Mo_SyncFirst_TRIGSRC -> CPT_esc_tasklink.RP_ESC_Tasklink_Mo_SyncFirst_TRIGSRC
    connect CPT_esc_tasklink.PP_ESC_Tasklink_Mo_SyncIni_TRIGSRC -> CPT_esc_tasklink.RP_ESC_Tasklink_Mo_SyncIni_TRIGSRC
    connect CPT_esc_tasklink.PP_ESC_Tasklink_Mo_SyncS0_TRIGSRC -> CPT_esc_tasklink.RP_ESC_Tasklink_Mo_SyncS0_TRIGSRC
    connect CPT_esc_tasklink.PP_ESC_Tasklink_Mo_SyncS1_TRIGSRC -> CPT_esc_tasklink.RP_ESC_Tasklink_Mo_SyncS1_TRIGSRC
    connect CPT_esc_tasklink.PP_ESC_Tasklink_SyncFirst_TRIGSRC -> CPT_Epm_Ladp.RP_ESC_Tasklink_SyncFirst_TRIGSRC
    connect CPT_esc_tasklink.PP_ESC_Tasklink_SyncFirst_TRIGSRC -> CPT_esc_tasklink.RP_ESC_Tasklink_SyncFirst_TRIGSRC
    connect CPT_esc_tasklink.PP_ESC_Tasklink_SyncIni_TRIGSRC -> CPT_ESC_EveCfg.RP_ESC_Tasklink_SyncIni_TRIGSRC
    connect CPT_esc_tasklink.PP_ESC_Tasklink_SyncIni_TRIGSRC -> CPT_ESC_OsTskActvnHndlr.RP_ESC_Tasklink_SyncIni_TRIGSRC
    connect CPT_esc_tasklink.PP_ESC_Tasklink_SyncIni_TRIGSRC -> CPT_Epm_Ladp.RP_ESC_Tasklink_SyncIni_TRIGSRC
    connect CPT_esc_tasklink.PP_ESC_Tasklink_SyncIni_TRIGSRC -> CPT_esc_stack.RP_ESC_Tasklink_SyncIni_TRIGSRC, variation-point={short-label=VP_ASC_CPT_esc_tasklink_PP_ESC_Tasklink_SyncIni_TRIGSRC_CPT_esc_stack_RP_ESC_Tasklink_SyncIni_TRIGSRC_ESC_SYNCTASK_SC_NEQ_1, sw-syscond=( ( ( /RB/PT/Common/SwSystemconsts/Adjustables/ESC_SYNCTASK_SC != 1) ) )&&( ( /RB/PT/Common/SwSystemconsts/Adjustables/ESC_SYNCTASK_SC != 1) )}
    connect CPT_esc_tasklink.PP_ESC_Tasklink_SyncIni_TRIGSRC -> CPT_esc_tasklink.RP_ESC_Tasklink_SyncIni_TRIGSRC
    connect CPT_esc_tasklink.PP_ESC_Tasklink_SyncPre_TRIGSRC -> CPT_ESC_EveCfg.RP_ESC_Tasklink_SyncPre_TRIGSRC
    connect CPT_esc_tasklink.PP_ESC_Tasklink_SyncPre_TRIGSRC -> CPT_Epm_Ladp.RP_ESC_Tasklink_SyncPre_TRIGSRC
    connect CPT_esc_tasklink.PP_ESC_Tasklink_SyncPre_TRIGSRC -> CPT_SysC_Ladp.RP_ESC_Tasklink_SyncPre_TRIGSRC
    connect CPT_esc_tasklink.PP_ESC_Tasklink_SyncPre_TRIGSRC -> CPT_esc_stack.RP_ESC_Tasklink_SyncPre_TRIGSRC, variation-point={short-label=VP_ASC_CPT_esc_tasklink_PP_ESC_Tasklink_SyncPre_TRIGSRC_CPT_esc_stack_RP_ESC_Tasklink_SyncPre_TRIGSRC_ESC_SYNCTASK_SC_NEQ_1, sw-syscond=( ( ( /RB/PT/Common/SwSystemconsts/Adjustables/ESC_SYNCTASK_SC != 1) ) )&&( ( /RB/PT/Common/SwSystemconsts/Adjustables/ESC_SYNCTASK_SC != 1) )}
    connect CPT_esc_tasklink.PP_ESC_Tasklink_SyncPre_TRIGSRC -> CPT_esc_tasklink.RP_ESC_Tasklink_SyncPre_TRIGSRC
    connect CPT_esc_tasklink.PP_ESC_Tasklink_SyncPre_TRIGSRC -> Epm_SwSStellantis.RP_ESC_Tasklink_SyncPre_Epm_TRIGSRC
    connect CPT_esc_tasklink.PP_ESC_Tasklink_SyncS0H_TRIGSRC -> CPT_esc_stack.RP_ESC_Tasklink_SyncS0H_TRIGSRC, variation-point={short-label=VP_ASC_CPT_esc_tasklink_PP_ESC_Tasklink_SyncS0H_TRIGSRC_CPT_esc_stack_RP_ESC_Tasklink_SyncS0H_TRIGSRC_ESC_SYNCTASK_SC_NEQ_1_AND, sw-syscond=( ( (( /RB/PT/Common/SwSystemconsts/Adjustables/ESC_SAMPLETICALCN_SC ==1) && ( /RB/PT/Common/SwSystemconsts/Adjustables/ESC_SYNCTASK_SC != 1)) ) )&&( ((/RB/PT/Common/SwSystemconsts/Adjustables/ESC_SAMPLETICALCN_SC==1) && (/RB/PT/Common/SwSystemconsts/Adjustables/ESC_SYNCTASK_SC!= 1)) )}
    connect CPT_esc_tasklink.PP_ESC_Tasklink_SyncS0H_TRIGSRC -> CPT_esc_tasklink.RP_ESC_Tasklink_SyncS0H_TRIGSRC, variation-point={short-label=VP_ASC_CPT_esc_tasklink_PP_ESC_Tasklink_SyncS0H_TRIGSRC_CPT_esc_tasklink_RP_ESC_Tasklink_SyncS0H_TRIGSRC_EPM_TDCDSTCLB_SC_EQ_1, sw-syscond=( ( ( /RB/PT/Common/SwSystemconsts/Adjustables/EPM_TDCDSTCLB_SC ==1) ) )&&( ( /RB/PT/Common/SwSystemconsts/Adjustables/EPM_TDCDSTCLB_SC ==1) )}
    connect CPT_esc_tasklink.PP_ESC_Tasklink_SyncS0_TRIGSRC -> CPT_Epm_Ladp.RP_ESC_Tasklink_SyncS0_TRIGSRC, variation-point={short-label=VP_ASC_CPT_esc_tasklink_PP_ESC_Tasklink_SyncS0_TRIGSRC_CPT_Epm_Ladp_RP_ESC_Tasklink_SyncS0_TRIGSRC_ESC_SWTSYNRTMEASMT_SC_EQ_1_AN, sw-syscond=( ( (( /RB/PT/Common/SwSystemconsts/Adjustables/ESC_SWTSYNRTMEASMT_SC ==1) && ( /RB/PT/Common/SwSystemconsts/Adjustables/CMBTYP_SY == /RB/PT/esc_tasklink/SwSystemconsts/CMBTYP_DS )) ) )&&( (( /RB/PT/Common/SwSystemconsts/Adjustables/ESC_SWTSYNRTMEASMT_SC ==1) && ( /RB/PT/Common/SwSystemconsts/Adjustables/CMBTYP_SY == /RB/PT/ESC/SwSystemconsts/CMBTYP_DS )) )}
    connect CPT_esc_tasklink.PP_ESC_Tasklink_SyncS0_TRIGSRC -> CPT_esc_stack.RP_ESC_Tasklink_SyncS0_TRIGSRC, variation-point={short-label=VP_ASC_CPT_esc_tasklink_PP_ESC_Tasklink_SyncS0_TRIGSRC_CPT_esc_stack_RP_ESC_Tasklink_SyncS0_TRIGSRC_ESC_SYNCTASK_SC_NEQ_1, sw-syscond=( ( ( /RB/PT/Common/SwSystemconsts/Adjustables/ESC_SYNCTASK_SC != 1) ) )&&( ( /RB/PT/Common/SwSystemconsts/Adjustables/ESC_SYNCTASK_SC != 1) )}
    connect CPT_esc_tasklink.PP_ESC_Tasklink_SyncS0_TRIGSRC -> CPT_esc_tasklink.RP_ESC_Tasklink_SyncS0_TRIGSRC
    connect CPT_esc_tasklink.PP_ESC_Tasklink_SyncS0_TRIGSRC -> Epm_SwSStellantis.RP_ESC_Tasklink_SyncS0_Epm_TRIGSRC
    connect CPT_esc_tasklink.PP_ESC_Tasklink_SyncS0_TRIGSRC -> IgnCl_SwSStellantis.RP_ESC_Tasklink_SyncS0_IgnCl_TRIGSRC
    connect CPT_esc_tasklink.PP_ESC_Tasklink_SyncS0_TRIGSRC -> InjSyG_SwSStellantis.RP_ESC_Tasklink_SyncS0_InjSyG_TRIGSRC
    connect CPT_esc_tasklink.PP_ESC_Tasklink_SyncS0_TRIGSRC -> InjVvGPfi_SwSStellantis.RP_ESC_Tasklink_SyncS0_InjVvGPfi_TRIGSRC
    connect CPT_esc_tasklink.PP_ESC_Tasklink_SyncS0_TRIGSRC -> InjVvG_SwSStellantis.RP_ESC_Tasklink_SyncS0_InjVvG_TRIGSRC
    connect CPT_esc_tasklink.PP_ESC_Tasklink_SyncS0_TRIGSRC -> IoSigIfAdapt_SwSStellantis.RP_ESC_Tasklink_SyncS0_IoSigIfAdapt_TRIGSRC
    connect CPT_esc_tasklink.PP_ESC_Tasklink_SyncS1_TRIGSRC -> CPT_esc_stack.RP_ESC_Tasklink_SyncS1_TRIGSRC, variation-point={short-label=VP_ASC_CPT_esc_tasklink_PP_ESC_Tasklink_SyncS1_TRIGSRC_CPT_esc_stack_RP_ESC_Tasklink_SyncS1_TRIGSRC_ESC_SYNCTASK_SC_NEQ_1, sw-syscond=( ( ( /RB/PT/Common/SwSystemconsts/Adjustables/ESC_SYNCTASK_SC != 1) ) )&&( ( /RB/PT/Common/SwSystemconsts/Adjustables/ESC_SYNCTASK_SC != 1) )}
    connect CPT_esc_tasklink.PP_ESC_Tasklink_SyncS1_TRIGSRC -> CPT_esc_tasklink.RP_ESC_Tasklink_SyncS1_TRIGSRC
    connect CPT_esc_tasklink.PP_ESC_Tasklink_SyncS1_TRIGSRC -> Epm_SwSStellantis.RP_ESC_Tasklink_SyncS1_Epm_TRIGSRC
    connect CPT_esc_tasklink.PP_ESC_Tasklink_SyncS1_TRIGSRC -> InjSyG_SwSStellantis.RP_ESC_Tasklink_SyncS1_InjSyG_TRIGSRC
    connect CPT_esc_tasklink.PP_ESC_Tasklink_SyncS1_TRIGSRC -> InjVvG_SwSStellantis.RP_ESC_Tasklink_SyncS1_InjVvG_TRIGSRC
    connect CPT_esc_tasklink.PP_ESC_Tasklink_SyncS1_TRIGSRC -> IoSigIfAdapt_SwSStellantis.RP_ESC_Tasklink_SyncS1_IoSigIfAdapt_TRIGSRC
    connect CPT_rba_OsArSchedExtn_OS.PP_rba_OsArSchedExtn_1Q1_IniEnd_TRIGSRC -> IoSigIfAdapt_SwSStellantis.RP_rba_OsArSchedExtn_1Q1_IniEnd_IoSigIfAdapt_TRIGSRC
    connect CPT_rbf_SftyHw_ShtOffPahPwrStg.PP_rbf_SftyHw_ShtOffPahPwrStg -> CPT_rbf_SftyHw_ErrMngtModl.RP_GetShtOffPathState_client1
    connect CPT_rbf_SftyHw_ShtOffPahPwrStg.PP_rbf_SftyHw_ShtOffPahPwrStg -> CPT_rbf_SftyHw_ErrMngtModl.RP_GetShtOffPathState_client2
    connect IoSigAdc_SwSStellantisParm.KeADCR_i_AirCdngPSnsrAdcInp -> AirCdngPSnsrAdcInpSwc.KeADCR_i_IdxNr
    connect IoSigAdc_SwSStellantisParm.KeADCR_i_BoostTemp1AdcInp -> BoostTemp1AdcInpSwc.KeADCR_i_IdxNr
    connect IoSigAdc_SwSStellantisParm.KeADCR_i_BoostTemp2AdcInp -> BoostTemp2AdcInpSwc.KeADCR_i_IdxNr
    connect IoSigAdc_SwSStellantisParm.KeADCR_i_BrkPdlPosnSnsrAdcInp -> BrkPdlPosnSnsrAdcInp.KeADCR_i_IdxNr
    connect IoSigAdc_SwSStellantisParm.KeADCR_i_CalInp1AdcInp -> CalInp1AdcInpSwc.KeADCR_i_IdxNr
    connect IoSigAdc_SwSStellantisParm.KeADCR_i_CalInp2AdcInp -> CalInp2AdcInpSwc.KeADCR_i_IdxNr
    connect IoSigAdc_SwSStellantisParm.KeADCR_i_CluSnsAdcInp -> CluSnsAdcInp.KeADCR_i_IdxNr
    connect IoSigAdc_SwSStellantisParm.KeADCR_i_CmprInletTemp -> CmprInletTempAdcInp.KeADCR_i_IdxNr
    connect IoSigAdc_SwSStellantisParm.KeADCR_i_ColdCrkCasePSnsrAdcInp -> ColdCrkCasePSnsrAdcInpSwc.KeADCR_i_IdxNr
    connect IoSigAdc_SwSStellantisParm.KeADCR_i_CoolEgrTAdcInp -> CoolEgrTAdcInpSwc.KeADCR_i_IdxNr
    connect IoSigAdc_SwSStellantisParm.KeADCR_i_Coolt3WayVlvAdcInp -> Coolt3WayVlvAdcInpSwc.KeADCR_i_IdxNr
    connect IoSigAdc_SwSStellantisParm.KeADCR_i_CooltInletTempAdcInp -> CooltInletTempAdcInpSwc.KeADCR_i_IdxNr
    connect IoSigAdc_SwSStellantisParm.KeADCR_i_CrkBattMonrAdcInp -> CrkBattMonrAdcInpSwc.KeADCR_i_IdxNr
    connect IoSigAdc_SwSStellantisParm.KeADCR_i_EngCooltTAdcInp -> EngCooltTAdcInpSwc.KeADCR_i_IdxNr
    connect IoSigAdc_SwSStellantisParm.KeADCR_i_EngSwtBattAdcInp -> EngSwtBattAdcInpSwc.KeADCR_i_IdxNr
    connect IoSigAdc_SwSStellantisParm.KeADCR_i_EvapLkChkMonSnsAdcInp -> EvapLkChkMonSnsAdcInpSwc.KeADCR_i_IdxNr
    connect IoSigAdc_SwSStellantisParm.KeADCR_i_FiveVoltAuxAdcInp -> FiveVoltAuxAdcInpSwc.KeADCR_i_IdxNr
    connect IoSigAdc_SwSStellantisParm.KeADCR_i_FiveVoltOutpAdcInp -> FiveVoltOutpAdcInpSwc.KeADCR_i_IdxNr
    connect IoSigAdc_SwSStellantisParm.KeADCR_i_FiveVoltSnsAdcInp -> FiveVoltSnsAdcInpSwc.KeADCR_i_IdxNr
    connect IoSigAdc_SwSStellantisParm.KeADCR_i_FuTankPSnsrAdcInp -> FuTankPSnsrAdcInpSwc.KeADCR_i_IdxNr
    connect IoSigAdc_SwSStellantisParm.KeADCR_i_GdiFuRailP1AdcInp -> GdiFuRailP1AdcInpSwc.KeADCR_i_IdxNr
    connect IoSigAdc_SwSStellantisParm.KeADCR_i_GdiFuRailP2AdcInp -> GdiFuRailP2AdcInpSwc.KeADCR_i_IdxNr
    connect IoSigAdc_SwSStellantisParm.KeADCR_i_HiTRadrOutlTSnsrAdcInp -> HiTRadrOutlTSnsrAdcInpSwc.KeADCR_i_IdxNr
    connect IoSigAdc_SwSStellantisParm.KeADCR_i_HoodAjarAdcInp -> HoodAjarAdcInpSwc.KeADCR_i_IdxNr
    connect IoSigAdc_SwSStellantisParm.KeADCR_i_IntkAirTAdcInp -> IntkAirTAdcInpSwc.KeADCR_i_IdxNr
    connect IoSigAdc_SwSStellantisParm.KeADCR_i_LoPFuSnsrAdcInp -> LoPFuSnsrAdcInpSwc.KeADCR_i_IdxNr
    connect IoSigAdc_SwSStellantisParm.KeADCR_i_MnfldAirPAdcInp -> MnfldAirPAdcInpSwc.KeADCR_i_IdxNr
    connect IoSigAdc_SwSStellantisParm.KeADCR_i_MnfldGasTAdcInp -> MnfldGasTAdcInpSwc.KeADCR_i_IdxNr
    connect IoSigAdc_SwSStellantisParm.KeADCR_i_OilPSnsrAdcInp -> OilPSnsrAdcInpSwc.KeADCR_i_IdxNr
    connect IoSigAdc_SwSStellantisParm.KeADCR_i_OilShutOffValveFbAdcInp -> OilShutOffValveFbAdcInp.KeADCR_i_IdxNr
    connect IoSigAdc_SwSStellantisParm.KeADCR_i_OilTSnsrAdcInp -> OilTSnsrAdcInpSwc.KeADCR_i_IdxNr
    connect IoSigAdc_SwSStellantisParm.KeADCR_i_PFIFuRailPressAdcInp -> PFIFuRailPressAdcInp.KeADCR_i_IdxNr
    connect IoSigAdc_SwSStellantisParm.KeADCR_i_PFIFuRailTempAdcInp -> PFIFuRailTempAdcInp.KeADCR_i_IdxNr
    connect IoSigAdc_SwSStellantisParm.KeADCR_i_PedlValSnsr1AdcInp -> PedlValSnsr1AdcInpSwc.KeADCR_i_IdxNr
    connect IoSigAdc_SwSStellantisParm.KeADCR_i_PedlValSnsr2AdcInp -> PedlValSnsr2AdcInpSwc.KeADCR_i_IdxNr
    connect IoSigAdc_SwSStellantisParm.KeADCR_i_PedlValSnsr2AuxAdcInp -> PedlValSnsr2AuxAdcInpSwc.KeADCR_i_IdxNr
    connect IoSigAdc_SwSStellantisParm.KeADCR_i_ReAxleTempSnsr -> ReAxleTempSnsrAdcInp.KeADCR_i_IdxNr
    connect IoSigAdc_SwSStellantisParm.KeADCR_i_SysU12VoltAdcInp -> SysU12VoltAdcInpSwc.KeADCR_i_IdxNr
    connect IoSigAdc_SwSStellantisParm.KeADCR_i_ThrIntkGasTAdcInp -> ThrIntkGasTAdcInpSwc.KeADCR_i_IdxNr
    connect IoSigAdc_SwSStellantisParm.KeADCR_i_ThrIntkPAdcInp -> ThrIntkPAdcInpSwc.KeADCR_i_IdxNr
    connect IoSigAdc_SwSStellantisParm.KeADCR_i_ThrPosnSnsr1AdcInp -> ThrPosnSnsr1AdcInpSwc.KeADCR_i_IdxNr
    connect IoSigAdc_SwSStellantisParm.KeADCR_i_ThrPosnSnsr2AdcInp -> ThrPosnSnsr2AdcInpSwc.KeADCR_i_IdxNr
    connect IoSigAdc_SwSStellantisParm.KeADCR_i_VarGeomTrbFb -> VarGeomTrbFb.KeADCR_i_IdxNr
    connect IoSigAdc_SwSStellantisParm.KeADCR_i_WgPosn1AdcInp -> WgPosn1AdcInpSwc.KeADCR_i_IdxNr
    connect IoSigAdc_SwSStellantisParm.KeADCR_i_WgPosn2 -> WgPosn2AdcInpSwc.KeADCR_i_IdxNr
    connect IoSigDioInp_SwSStellantisParam.KeDIOR_i_DigInpBrkSw -> BrkSwDigInp.ChCal
    connect IoSigDioInp_SwSStellantisParam.KeDIOR_i_DigInpCluInterLockSw -> CluInterLockSwDigInp.ChCal
    connect IoSigDioInp_SwSStellantisParam.KeDIOR_i_DigInpDynoFuDsblReqSw -> DynoFuDsblReqSwDigInp.ChCal
    connect IoSigDioInp_SwSStellantisParam.KeDIOR_i_DigInpECM_WakeUp -> ECM_WakeUpDigInp.ChCal
    connect IoSigDioInp_SwSStellantisParam.KeDIOR_i_DigInpFuDoorSw -> FuDoorSwDigInp.ChCal
    connect IoSigDioInp_SwSStellantisParam.KeDIOR_i_DigInpIgnRunStrtSw -> IgnRunStrtSwDigInp.ChCal
    connect IoSigDioInp_SwSStellantisParam.KeDIOR_i_DigInpNVLD_Sw -> NVLD_SwDigInp.ChCal
    connect IoSigDioInp_SwSStellantisParam.KeDIOR_i_DigInpStrtrRlyFb -> StrtrRlyFbDigInp.ChCal
    connect IoSigDioOutp_SwSStellantisParam.KeDIOR_i_DigOutpAC_CluRly -> AC_CluRlyDigOutp.ChCal
    connect IoSigDioOutp_SwSStellantisParam.KeDIOR_i_DigOutpDMTLLkPmp -> DMTLLkPmpDigOutp.ChCal
    connect IoSigDioOutp_SwSStellantisParam.KeDIOR_i_DigOutpDualFuTankEnblRly -> DualFuTankEnblRlyDigOutp.ChCal
    connect IoSigDioOutp_SwSStellantisParam.KeDIOR_i_DigOutpELCM_ChgOvrVlv -> ELCM_ChgOvrVlvDigOutp.ChCal
    connect IoSigDioOutp_SwSStellantisParam.KeDIOR_i_DigOutpElectcVacPmpRly -> ElectcVacPmpRlyDigOutp.ChCal
    connect IoSigDioOutp_SwSStellantisParam.KeDIOR_i_DigOutpFuDoor -> FuDoorDigOutp.ChCal
    connect IoSigDioOutp_SwSStellantisParam.KeDIOR_i_DigOutpFuTankIsolnVlv -> FuTankIsolnVlvDigOutp.ChCal
    connect IoSigDioOutp_SwSStellantisParam.KeDIOR_i_DigOutpInrushCircRly -> InrushCircRlyDigOutp.ChCal
    connect IoSigDioOutp_SwSStellantisParam.KeDIOR_i_DigOutpLoPresFuPmpRly -> LoPresFuPmpRlyDigOutp.ChCal
    connect IoSigDioOutp_SwSStellantisParam.KeDIOR_i_DigOutpMaiRly -> MaiRlyDigOutp.ChCal
    connect IoSigDioOutp_SwSStellantisParam.KeDIOR_i_DigOutpMakeUpAirVlv -> MakeUpAirVlvDigOutp.ChCal
    connect IoSigDioOutp_SwSStellantisParam.KeDIOR_i_DigOutpOBD_PurgVentVlv -> OBD_PurgVentVlvDigOutp.ChCal
    connect IoSigDioOutp_SwSStellantisParam.KeDIOR_i_DigOutpOilShutOffVlv -> OilShutOffVlvDigOutp.ChCal
    connect IoSigDioOutp_SwSStellantisParam.KeDIOR_i_DigOutpRadrFanRlyHiSpd -> RadrFanRlyHiSpdDigOutp.ChCal
    connect IoSigDioOutp_SwSStellantisParam.KeDIOR_i_DigOutpSecdAirPmpRly -> SecdAirPmpRlyDigOutp.ChCal
    connect IoSigDioOutp_SwSStellantisParam.KeDIOR_i_DigOutpSecdAirShutOffSoln1 -> SecdAirShutOffSoln1DigOutp.ChCal
    connect IoSigDioOutp_SwSStellantisParam.KeDIOR_i_DigOutpSrgSoln1 -> SrgSoln1DigOutp.ChCal
    connect IoSigDioOutp_SwSStellantisParam.KeDIOR_i_DigOutpSrgSoln2 -> SrgSoln2DigOutp.ChCal
    connect IoSigDioOutp_SwSStellantisParam.KeDIOR_i_DigOutpStrtrRly -> StrtrRlyDigOutp.ChCal
    connect IoSigDioOutp_SwSStellantisParam.KeDIOR_i_DigOutpSwilEngMnt1 -> SwilEngMnt1DigOutp.ChCal
    connect IoSigDioOutp_SwSStellantisParam.KeDIOR_i_DigOutpSwilEngMnt2 -> SwilEngMnt2DigOutp.ChCal
    connect IoSigDioOutp_SwSStellantisParam.KeDIOR_i_DigOutpTOH -> TOH_ShutOffVlvDigOutp.ChCal
    connect IoSigDioOutp_SwSStellantisParam.KeDIOR_i_DigOutpVapBlockingVlv -> VapBlockingVlvDigOutp.ChCal
    connect IoSigHbrdg_SwSStellantisParam.KeDIOR_i_Hbrdg_Coold_EGR -> Hbrdg_Coold_EGR.ChCal
    connect IoSigHbrdg_SwSStellantisParam.KeDIOR_i_Hbrdg_DP -> Hbrdg_DP.ChCal
    connect IoSigHbrdg_SwSStellantisParam.KeDIOR_i_Hbrdg_ETC_Motor -> Hbrdg_ETC_Motor.ChCal
    connect IoSigHbrdg_SwSStellantisParam.KeDIOR_i_Hbrdg_VarGeomTrb -> Hbrdg_VarGeomTrb.ChCal
    connect IoSigHbrdg_SwSStellantisParam.KeDIOR_i_Hbrdg_Wg1 -> Hbrdg_Wg1.ChCal
    connect IoSigPwmInp_SwSStellantisParm.KeDIOR_i_AllGrPosnSnsr1PwmInp -> AllGrPosnSnsr1PwmInp.ChCal
    connect IoSigPwmInp_SwSStellantisParm.KeDIOR_i_AllGrPosnSnsr2PwmInp -> AllGrPosnSnsr2PwmInp.ChCal
    connect IoSigPwmInp_SwSStellantisParm.KeDIOR_i_ElecPhsrDiagPwmInp -> ElecPhsrDiagPwmInp.ChCal
    connect IoSigPwmInp_SwSStellantisParm.KeDIOR_i_FPCMFb1PwmInp -> FPCMFb1PwmInp.ChCal
    connect IoSigPwmInp_SwSStellantisParm.KeDIOR_i_OilLvlSnsrPwmInp -> OilLvlSnsrPwmInp.ChCal
    connect IoSigPwmOutp_SwSStellantisParm.KeDIOR_i_HTR_MeclWtrPmpActr -> HTR_MeclWtrPmpActrPwmOutp.IoHwAbPwmOutpCal
    connect IoSigPwmOutp_SwSStellantisParm.KeDIOR_i_PwmOutpAlterFieCtrl -> AlterFieCtrlPwmOutp.IoHwAbPwmOutpCal
    connect IoSigPwmOutp_SwSStellantisParm.KeDIOR_i_PwmOutpELCM_VacPmp -> ELCM_VacPmpPwmOutp.IoHwAbPwmOutpCal
    connect IoSigPwmOutp_SwSStellantisParm.KeDIOR_i_PwmOutpElecPhsrMtrCmdOutp -> ElecPhsrMtrCmdOutpPwmOutp.IoHwAbPwmOutpCal
    connect IoSigPwmOutp_SwSStellantisParm.KeDIOR_i_PwmOutpFuPmpCtlMdul2Cmd -> FuPmpCtlMdul2CmdPwmOutp.IoHwAbPwmOutpCal
    connect IoSigPwmOutp_SwSStellantisParm.KeDIOR_i_PwmOutpFuPmpCtlMdulCmd -> FuPmpCtlMdulCmdPwmOutp.IoHwAbPwmOutpCal
    connect IoSigPwmOutp_SwSStellantisParm.KeDIOR_i_PwmOutpHTR_TempCtrlVlvSoln -> HTR_TempCtrlVlvSolnPwmOutp.IoHwAbPwmOutpCal
    connect IoSigPwmOutp_SwSStellantisParm.KeDIOR_i_PwmOutpPurgSoln -> PurgSolnPwmOutp.IoHwAbPwmOutpCal
    connect IoSigPwmOutp_SwSStellantisParm.KeDIOR_i_PwmOutpPurgSoln2 -> PurgSoln2PwmOutp.IoHwAbPwmOutpCal
    connect IoSigPwmOutp_SwSStellantisParm.KeDIOR_i_PwmOutpRadrFanCtrlPwm -> RadrFanCtrlPwmPwmOutp.IoHwAbPwmOutpCal
    connect IoSigPwmOutp_SwSStellantisParm.KeDIOR_i_PwmOutpVarOilSoln -> VarOilSolnPwmOutp.IoHwAbPwmOutpCal
    connect IoSigPwmOutp_SwSStellantisParm.KeDIOR_i_PwmOutpVvtExh1 -> VvtExh1PwmOutp.IoHwAbPwmOutpCal
    connect IoSigPwmOutp_SwSStellantisParm.KeDIOR_i_PwmOutpVvtIntk1 -> VvtIntk1PwmOutp.IoHwAbPwmOutpCal
    connect IoSigPwmOutp_SwSStellantisParm.KeDIOR_i_PwmOutpWgSoln -> WgSolnPwmOutp.IoHwAbPwmOutpCal
    connect SentStack_SwSStellantisParm.KeSNTR_e_SENTCh0 -> CEGR_PosnSns.KeSNTR_i_ChIdx
    connect SentStack_SwSStellantisParm.KeSNTR_e_SENTCh1 -> EGRCoolr_DeltAbsPresSnsr.KeSNTR_i_ChIdx
    connect SentStack_SwSStellantisParm.KeSNTR_e_SENTCh2 -> DP_VlvPosnSns.KeSNTR_i_ChIdx
    connect SentStack_SwSStellantisParm.KeSNTR_e_SENTCh3 -> MAF_Hum_Snsr.KeSNTR_i_ChIdx
    connect SentStack_SwSStellantisParm.KeSNTR_e_SENTCh4 -> GPF_DeltAbsPresSnsr1.KeSNTR_i_ChIdx
    connect SentStack_SwSStellantisParm.KeSNTR_e_SENTCh5 -> GPF_DeltAbsPresSnsr2.KeSNTR_i_ChIdx
    delegate CPT_ComScl_EngLin_Scl.PP_COM_Tx_ECM_AGS2_DEMAND <-> outer port PP_COM_Tx_ECM_AGS2_DEMAND
    delegate CPT_ComScl_EngLin_Scl.PP_COM_Tx_ECM_AGS_DEMAND <-> outer port PP_COM_Tx_ECM_AGS_DEMAND
    delegate CPT_ComScl_EngLin_Scl.PP_COM_Tx_ECM_EEV <-> outer port PP_COM_Tx_ECM_EEV
    delegate CPT_ComScl_EngLin_Scl.PP_COM_Tx_ECM_LCVM <-> outer port PP_COM_Tx_ECM_LCVM
    delegate CPT_ComScl_EngLin_Scl.PP_COM_Tx_ECM_LCVM2 <-> outer port PP_COM_Tx_ECM_LCVM2
    delegate CPT_ComScl_EngLin_Scl.PP_COM_Tx_HAPM_REQ <-> outer port PP_COM_Tx_HAPM_REQ
    delegate CPT_ComScl_EngLin_Scl.PP_COM_Tx_LTRP_REQ <-> outer port PP_COM_Tx_LTRP_REQ
    delegate CPT_ComScl_EngLin_Scl.PP_COM_Tx_MASTER_PLA <-> outer port PP_COM_Tx_MASTER_PLA
    delegate CPT_ComScl_EngLin_Scl.PP_COM_Tx_PCPM_REQ <-> outer port PP_COM_Tx_PCPM_REQ
    delegate CPT_ComScl_NetMtrx2_Scl.PP_COM_Tx_ENGINE_FD_1_FD14 <-> outer port PP_COM_Tx_ENGINE_FD_1_FD14
    delegate CPT_ComScl_NetMtrx2_Scl.PP_COM_Tx_ENGINE_FD_3_FD14 <-> outer port PP_COM_Tx_ENGINE_FD_3_FD14
    delegate CPT_ComScl_NetMtrx2_Scl.PP_COM_Tx_ENGINE_FD_7_FD14 <-> outer port PP_COM_Tx_ENGINE_FD_7_FD14
    delegate CPT_ComScl_NetMtrx3_Scl.PP_COM_Tx_ENGINE_FD_1_FD16 <-> outer port PP_COM_Tx_ENGINE_FD_1_FD16
    delegate CPT_ComScl_NetMtrx3_Scl.PP_COM_Tx_ENGINE_FD_3_FD16 <-> outer port PP_COM_Tx_ENGINE_FD_3_FD16
    delegate CPT_ComScl_NetMtrx3_Scl.PP_COM_Tx_ENGINE_FD_{6..8}_FD16 <-> outer port PP_COM_Tx_ENGINE_FD_{6..8}_FD16
    delegate CPT_ComScl_NetMtrx3_Scl.PP_COM_Tx_ENGINE_HYBD_FD_3_FD16 <-> outer port PP_COM_Tx_ENGINE_HYBD_FD_3_FD16
    delegate CPT_ComScl_NetMtrx3_Scl.PP_COM_Tx_ENGINE_HYBD_FD_4_FD16 <-> outer port PP_COM_Tx_ENGINE_HYBD_FD_4_FD16
    delegate CPT_ComScl_NetMtrx3_Scl.PP_COM_Tx_OBD_CONTENT_FRAME_FD16 <-> outer port PP_COM_Tx_OBD_CONTENT_FRAME_FD16
    delegate CPT_ComScl_NetMtrx_Scl.PP_COM_Tx_ENGINE_FD_1_FD3 <-> outer port PP_COM_Tx_ENGINE_FD_1_FD3
    delegate CPT_ComScl_NetMtrx_Scl.PP_COM_Tx_ENGINE_FD_3_FD3 <-> outer port PP_COM_Tx_ENGINE_FD_3_FD3
    delegate CPT_ComScl_NetMtrx_Scl.PP_COM_Tx_ENGINE_FD_6 <-> outer port PP_COM_Tx_ENGINE_FD_6
    delegate CPT_ComScl_NetMtrx_Scl.PP_COM_Tx_ENGINE_FD_7_FD3 <-> outer port PP_COM_Tx_ENGINE_FD_7_FD3
    delegate CPT_ComScl_NetMtrx_Scl.PP_COM_Tx_ENGINE_FD_8 <-> outer port PP_COM_Tx_ENGINE_FD_8
    delegate CPT_ComScl_NetMtrx_Scl.PP_COM_Tx_ENGINE_FD_9 <-> outer port PP_COM_Tx_ENGINE_FD_9
    delegate CPT_ComScl_NetMtrx_Scl.PP_COM_Tx_ENGINE_FD_DIESEL <-> outer port PP_COM_Tx_ENGINE_FD_DIESEL
    delegate CPT_ComScl_NetMtrx_Scl.PP_COM_Tx_ENGINE_HYBD_FD_3 <-> outer port PP_COM_Tx_ENGINE_HYBD_FD_3
    delegate CPT_ComScl_NetMtrx_Scl.PP_COM_Tx_ENGINE_HYBD_FD_4 <-> outer port PP_COM_Tx_ENGINE_HYBD_FD_4
    delegate CPT_ComScl_NetMtrx_Scl.PP_COM_Tx_OBD_CONTENT_FRAME <-> outer port PP_COM_Tx_OBD_CONTENT_FRAME
    delegate CPT_ComScl_NetMtrx_Scl.PP_COM_Tx_PDC_INFO_FD_ECM <-> outer port PP_COM_Tx_PDC_INFO_FD_ECM
    delegate CPT_ComScl_EngLin_Scl.RP_COM_Rx_AGS2_ECM_STATUS <-> outer port RP_COM_Rx_AGS2_ECM_STATUS
    delegate CPT_ComScl_EngLin_Scl.RP_COM_Rx_AGS_ECM_STATUS <-> outer port RP_COM_Rx_AGS_ECM_STATUS
    delegate CPT_ComScl_EngLin_Scl.RP_COM_Rx_EEV1_ECM <-> outer port RP_COM_Rx_EEV1_ECM
    delegate CPT_ComScl_EngLin_Scl.RP_COM_Rx_EEV2_ECM <-> outer port RP_COM_Rx_EEV2_ECM
    delegate CPT_ComScl_EngLin_Scl.RP_COM_Rx_HAPM_STAT <-> outer port RP_COM_Rx_HAPM_STAT
    delegate CPT_ComScl_EngLin_Scl.RP_COM_Rx_HAPM_VER <-> outer port RP_COM_Rx_HAPM_VER
    delegate CPT_ComScl_EngLin_Scl.RP_COM_Rx_LCVM2_ECM <-> outer port RP_COM_Rx_LCVM2_ECM
    delegate CPT_ComScl_EngLin_Scl.RP_COM_Rx_LCVM_ECM <-> outer port RP_COM_Rx_LCVM_ECM
    delegate CPT_ComScl_EngLin_Scl.RP_COM_Rx_LTRP_STAT <-> outer port RP_COM_Rx_LTRP_STAT
    delegate CPT_ComScl_EngLin_Scl.RP_COM_Rx_LTRP_VER <-> outer port RP_COM_Rx_LTRP_VER
    delegate CPT_ComScl_EngLin_Scl.RP_COM_Rx_PCPM_Stat <-> outer port RP_COM_Rx_PCPM_Stat
    delegate CPT_ComScl_EngLin_Scl.RP_COM_Rx_PCPM_VER <-> outer port RP_COM_Rx_PCPM_VER
    delegate CPT_ComScl_EngLin_Scl.RP_COM_Rx_PLA_INFO <-> outer port RP_COM_Rx_PLA_INFO
    delegate CPT_ComScl_NetMtrx2_Scl.RP_COM_Rx_ADAS_FD_HMI_FD14 <-> outer port RP_COM_Rx_ADAS_FD_HMI_FD14
    delegate CPT_ComScl_NetMtrx2_Scl.RP_COM_Rx_BRAKE_FD_1_FD14 <-> outer port RP_COM_Rx_BRAKE_FD_1_FD14
    delegate CPT_ComScl_NetMtrx2_Scl.RP_COM_Rx_HYBRID_POWERTRAIN1_FD14 <-> outer port RP_COM_Rx_HYBRID_POWERTRAIN1_FD14
    delegate CPT_ComScl_NetMtrx3_Scl.RP_COM_Rx_HYBRID_THERMAL_COMMAND_FD16 <-> outer port RP_COM_Rx_HYBRID_THERMAL_COMMAND_FD16
    delegate CPT_ComScl_NetMtrx_Scl.RP_COM_Rx_ADAS_FD_HMI_FD3 <-> outer port RP_COM_Rx_ADAS_FD_HMI_FD3
    delegate CPT_ComScl_NetMtrx_Scl.RP_COM_Rx_ADAS_FD_INFO2 <-> outer port RP_COM_Rx_ADAS_FD_INFO2
    delegate CPT_ComScl_NetMtrx_Scl.RP_COM_Rx_ADCM_FD_A4 <-> outer port RP_COM_Rx_ADCM_FD_A4
    delegate CPT_ComScl_NetMtrx_Scl.RP_COM_Rx_ASCM_FD_2 <-> outer port RP_COM_Rx_ASCM_FD_2
    delegate CPT_ComScl_NetMtrx_Scl.RP_COM_Rx_BCM_FD_{10..12} <-> outer port RP_COM_Rx_BCM_FD_{10..12}
    delegate CPT_ComScl_NetMtrx_Scl.RP_COM_Rx_BCM_FD_14 <-> outer port RP_COM_Rx_BCM_FD_14
    delegate CPT_ComScl_NetMtrx_Scl.RP_COM_Rx_BCM_FD_23 <-> outer port RP_COM_Rx_BCM_FD_23
    delegate CPT_ComScl_NetMtrx_Scl.RP_COM_Rx_BCM_FD_26 <-> outer port RP_COM_Rx_BCM_FD_26
    delegate CPT_ComScl_NetMtrx_Scl.RP_COM_Rx_BCM_FD_27 <-> outer port RP_COM_Rx_BCM_FD_27
    delegate CPT_ComScl_NetMtrx_Scl.RP_COM_Rx_BCM_FD_29 <-> outer port RP_COM_Rx_BCM_FD_29
    delegate CPT_ComScl_NetMtrx_Scl.RP_COM_Rx_BCM_FD_3 <-> outer port RP_COM_Rx_BCM_FD_3
    delegate CPT_ComScl_NetMtrx_Scl.RP_COM_Rx_BCM_FD_4 <-> outer port RP_COM_Rx_BCM_FD_4
    delegate CPT_ComScl_NetMtrx_Scl.RP_COM_Rx_BCM_FD_6 <-> outer port RP_COM_Rx_BCM_FD_6
    delegate CPT_ComScl_NetMtrx_Scl.RP_COM_Rx_BCM_FD_7 <-> outer port RP_COM_Rx_BCM_FD_7
    delegate CPT_ComScl_NetMtrx_Scl.RP_COM_Rx_BRAKE_FD_6_FD3 <-> outer port RP_COM_Rx_BRAKE_FD_6_FD3
    delegate CPT_ComScl_NetMtrx_Scl.RP_COM_Rx_CFG_DATA_CODE_REQUEST <-> outer port RP_COM_Rx_CFG_DATA_CODE_REQUEST
    delegate CPT_ComScl_NetMtrx_Scl.RP_COM_Rx_CVPAM_FD_Info <-> outer port RP_COM_Rx_CVPAM_FD_Info
    delegate CPT_ComScl_NetMtrx_Scl.RP_COM_Rx_DRIVETRAIN_FD_3 <-> outer port RP_COM_Rx_DRIVETRAIN_FD_3
    delegate CPT_ComScl_NetMtrx_Scl.RP_COM_Rx_EPS_FD_2 <-> outer port RP_COM_Rx_EPS_FD_2
    delegate CPT_ComScl_NetMtrx_Scl.RP_COM_Rx_FOTA_MASTER <-> outer port RP_COM_Rx_FOTA_MASTER
    delegate CPT_ComScl_NetMtrx_Scl.RP_COM_Rx_GPF_DATA_FD_1 <-> outer port RP_COM_Rx_GPF_DATA_FD_1
    delegate CPT_ComScl_NetMtrx_Scl.RP_COM_Rx_HVBATTERY{1..3} <-> outer port RP_COM_Rx_HVBATTERY{1..3}
    delegate CPT_ComScl_NetMtrx_Scl.RP_COM_Rx_HVBATTERY5 <-> outer port RP_COM_Rx_HVBATTERY5
    delegate CPT_ComScl_NetMtrx_Scl.RP_COM_Rx_HV_CHARGER1 <-> outer port RP_COM_Rx_HV_CHARGER1
    delegate CPT_ComScl_NetMtrx_Scl.RP_COM_Rx_HYBRID_DISPLAY <-> outer port RP_COM_Rx_HYBRID_DISPLAY
    delegate CPT_ComScl_NetMtrx_Scl.RP_COM_Rx_HYBRID_HVAC <-> outer port RP_COM_Rx_HYBRID_HVAC
    delegate CPT_ComScl_NetMtrx_Scl.RP_COM_Rx_HYBRID_THERMAL_COMMAND <-> outer port RP_COM_Rx_HYBRID_THERMAL_COMMAND
    delegate CPT_ComScl_NetMtrx_Scl.RP_COM_Rx_IBS3_DATA_1 <-> outer port RP_COM_Rx_IBS3_DATA_1
    delegate CPT_ComScl_NetMtrx_Scl.RP_COM_Rx_IBS3_DATA_2 <-> outer port RP_COM_Rx_IBS3_DATA_2
    delegate CPT_ComScl_NetMtrx_Scl.RP_COM_Rx_IMMO_CODE_RESPONSE <-> outer port RP_COM_Rx_IMMO_CODE_RESPONSE
    delegate CPT_ComScl_NetMtrx_Scl.RP_COM_Rx_IMMO_SOP_REQUEST <-> outer port RP_COM_Rx_IMMO_SOP_REQUEST
    delegate CPT_ComScl_NetMtrx_Scl.RP_COM_Rx_IMPACT_INFO <-> outer port RP_COM_Rx_IMPACT_INFO
    delegate CPT_ComScl_NetMtrx_Scl.RP_COM_Rx_IPC_FD_1 <-> outer port RP_COM_Rx_IPC_FD_1
    delegate CPT_ComScl_NetMtrx_Scl.RP_COM_Rx_IPC_FD_4 <-> outer port RP_COM_Rx_IPC_FD_4
    delegate CPT_ComScl_NetMtrx_Scl.RP_COM_Rx_IPC_VEHICLE_SETUP <-> outer port RP_COM_Rx_IPC_VEHICLE_SETUP
    delegate CPT_ComScl_NetMtrx_Scl.RP_COM_Rx_PT_SYSTEM_FD_1_FD3 <-> outer port RP_COM_Rx_PT_SYSTEM_FD_1_FD3
    delegate CPT_ComScl_NetMtrx_Scl.RP_COM_Rx_RFHUB_FD_1 <-> outer port RP_COM_Rx_RFHUB_FD_1
    delegate CPT_ComScl_NetMtrx_Scl.RP_COM_Rx_STEERING1 <-> outer port RP_COM_Rx_STEERING1
    delegate CPT_ComScl_NetMtrx_Scl.RP_COM_Rx_TELEMATIC_FD_1 <-> outer port RP_COM_Rx_TELEMATIC_FD_1
    delegate CPT_ComScl_NetMtrx_Scl.RP_COM_Rx_TELEMATIC_FD_11 <-> outer port RP_COM_Rx_TELEMATIC_FD_11
    delegate CPT_ComScl_NetMtrx_Scl.RP_COM_Rx_TELEMATIC_FD_14 <-> outer port RP_COM_Rx_TELEMATIC_FD_14
    delegate CPT_ComScl_NetMtrx_Scl.RP_COM_Rx_TELEMATIC_FD_5 <-> outer port RP_COM_Rx_TELEMATIC_FD_5
    delegate CPT_ComScl_NetMtrx_Scl.RP_COM_Rx_VSIM_FD_1 <-> outer port RP_COM_Rx_VSIM_FD_1
